VERSION ""

NS_ :

BS_:

BU_: CH DIPF DIPR ETH FC HVI HVS PARTY SDCV VEH VIRT

BO_ 1343 BMS_alertLog: 8 VEH
 SG_ BMS_a025_disSna m25 : 63|1@1+ (1,0) [0|1] ""  gtw
 SG_ BMS_a178_disMia m178 : 63|1@1+ (1,0) [0|1] ""  gtw
 SG_ BMS_a084_vmModuleError m84 : 62|1@1+ (1,0) [0|1] ""  gtw
 SG_ BMS_a025_diSna m25 : 62|1@1+ (1,0) [0|1] ""  gtw
 SG_ BMS_a178_diMia m178 : 62|1@1+ (1,0) [0|1] ""  gtw
 SG_ BMS_a084_udsModuleError m84 : 61|1@1+ (1,0) [0|1] ""  gtw
 SG_ BMS_a084_thermalModuleError m84 : 60|1@1+ (1,0) [0|1] ""  gtw
 SG_ BMS_a084_sleepModuleError m84 : 59|1@1+ (1,0) [0|1] ""  gtw
 SG_ BMS_a084_shuntModuleError m84 : 58|1@1+ (1,0) [0|1] ""  gtw
 SG_ BMS_a084_sensorModuleError m84 : 57|1@1+ (1,0) [0|1] ""  gtw
 SG_ BMS_a082_totalAlertCount m82 : 56|8@1+ (1,0) [0|255] ""  gtw
 SG_ BMS_a084_selfTestModuleError m84 : 56|1@1+ (1,0) [0|1] ""  gtw
 SG_ BMS_a081_totalAlertCount m81 : 56|8@1+ (1,0) [0|255] ""  gtw
 SG_ BMS_a024_packCurrent m24 : 56|8@1- (1,-476) [-1496|544] "A"  gtw
 SG_ BMS_a123_packMinus m123 : 56|8@1- (4,0) [-512|508] "V"  gtw
 SG_ BMS_a039_state m39 : 56|4@1+ (1,0) [0|9] ""  gtw
 SG_ BMS_a084_powerModuleError m84 : 55|1@1+ (1,0) [0|1] ""  gtw
 SG_ BMS_a042_write m42 : 54|1@1+ (1,0) [0|1] ""  gtw
 SG_ BMS_a084_nvramModuleError m84 : 54|1@1+ (1,0) [0|1] ""  gtw
 SG_ BMS_a042_supervisor m42 : 53|1@1+ (1,0) [0|1] ""  gtw
 SG_ BMS_a084_isolationModuleError m84 : 53|1@1+ (1,0) [0|1] ""  gtw
 SG_ BMS_a084_energyModuleError m84 : 52|1@1+ (1,0) [0|1] ""  gtw
 SG_ BMS_a166_dcLinkNegativeV m166 : 52|12@1- (0.25,0) [-512|511.75] "V"  gtw
 SG_ BMS_a165_dcLinkNegativeV m165 : 52|12@1- (0.25,0) [-512|511.75] "V"  gtw
 SG_ BMS_a105_inletTemp m105 : 52|8@1+ (0.5,0) [0|127.5] "C"  gtw
 SG_ BMS_a178_energyError m178 : 51|11@1- (0.1,0) [-102.4|102.3] "kJ"  gtw
 SG_ BMS_a025_energyError m25 : 51|11@1- (0.1,0) [-102.4|102.3] "kJ"  gtw
 SG_ BMS_a168_fcLinkNegativeV m168 : 51|11@1- (0.5,0) [-512|511.5] "V"  gtw
 SG_ BMS_a084_driveLimitsModuleError m84 : 51|1@1+ (1,0) [0|1] ""  gtw
 SG_ BMS_a062_maxBrickVoltage m62 : 51|12@1+ (0.002,0) [0|5] "V"  gtw
 SG_ BMS_a167_fcLinkNegativeV m167 : 51|11@1- (0.5,0) [-512|511.5] "V"  gtw
 SG_ BMS_a084_contactorsModuleError m84 : 50|1@1+ (1,0) [0|1] ""  gtw
 SG_ BMS_a123_state m123 : 50|4@1+ (1,0) [0|9] ""  gtw
 SG_ BMS_a042_master m42 : 49|4@1+ (1,0) [0|15] ""  gtw
 SG_ BMS_a084_chargeStateModuleError m84 : 49|1@1+ (1,0) [0|1] ""  gtw
 SG_ BMS_a084_chargeModuleError m84 : 48|1@1+ (1,0) [0|1] ""  gtw
 SG_ BMS_a138_ovBrickV m138 : 48|16@1+ (7.6293945313e-05,0) [0|4.9999237061] "V"  gtw
 SG_ BMS_a000_alertDataW2 m0 : 48|16@1+ (1,0) [0|65535] ""  X
 SG_ BMS_a130_hviErrorCount m130 : 48|16@1+ (1,0) [0|65535] ""  gtw
 SG_ BMS_a026_deltaPackCurrentPrev m26 : 48|13@1+ (1,0) [0|8191] "A"  gtw
 SG_ BMS_a077_packCurrent m77 : 48|8@1+ (8,-1496) [-1496|540] "A"  gtw
 SG_ BMS_a144_BMS_minor_version m144 : 48|16@1+ (1,0) [0|65535] ""  gtw
 SG_ BMS_a134_maxBrickT m134 : 48|5@1+ (3,-25) [-25|68] "C"  gtw
 SG_ BMS_a137_uvBrickV m137 : 48|16@1+ (7.6293945313e-05,0) [0|4.9999237061] "V"  gtw
 SG_ BMS_a082_fourthAlertId m82 : 48|8@1+ (1,0) [0|180] ""  gtw
 SG_ BMS_a042_data m42 : 48|1@1+ (1,0) [0|1] ""  gtw
 SG_ BMS_a162_socThreshold m162 : 48|16@1+ (1,0) [0|100] "%"  gtw
 SG_ BMS_a034_state m34 : 48|4@1+ (1,0) [0|9] ""  gtw
 SG_ BMS_a146_uvBrickV m146 : 48|16@1+ (7.6293945313e-05,0) [0|4.9999237061] "V"  gtw
 SG_ BMS_a171_stackIndex m171 : 48|8@1+ (1,0) [0|255] ""  gtw
 SG_ BMS_a081_fourthBlockingAlertId m81 : 48|8@1+ (1,0) [0|180] ""  gtw
 SG_ BMS_a039_maxBrickV m39 : 48|8@1+ (0.01,2) [2|4.55] "V"  gtw
 SG_ BMS_a084_brickModuleError m84 : 47|1@1+ (1,0) [0|1] ""  gtw
 SG_ BMS_a084_bmbModuleError m84 : 46|1@1+ (1,0) [0|1] ""  gtw
 SG_ BMS_a084_bsmModuleError m84 : 45|1@1+ (1,0) [0|1] ""  gtw
 SG_ BMS_a105_avgBrickTModule4 m105 : 44|8@1+ (0.5,0) [0|127.5] "C"  gtw
 SG_ BMS_a062_maxBrickVId m62 : 44|7@1+ (1,1) [1|128] ""  gtw
 SG_ BMS_a084_balanceModuleError m84 : 44|1@1+ (1,0) [0|1] ""  gtw
 SG_ BMS_a105_tSenseFailedModule4 m105 : 43|1@1+ (1,0) [0|1] ""  gtw
 SG_ BMS_a084_adcModuleError m84 : 43|1@1+ (1,0) [0|1] ""  gtw
 SG_ BMS_a151_isoNegativeR m151 : 42|10@1+ (10,0) [0|4000] "kOhm"  gtw
 SG_ BMS_a051_bms3V0Ref m51 : 40|12@1+ (0.001,0) [0|4.095] "V"  gtw
 SG_ BMS_a178_batteryPower m178 : 40|11@1- (1,0) [-1024|1023] "kW"  gtw
 SG_ BMS_a019_maxBrickTID m19 : 40|5@1+ (1,0) [0|31] ""  gtw
 SG_ BMS_a166_dcLinkPositiveV m166 : 40|12@1- (0.25,0) [-512|511.75] "V"  gtw
 SG_ BMS_a024_avgDvPrev m24 : 40|16@1- (0.0001,0) [-3.2768|3.2767] "V"  gtw
 SG_ BMS_a165_dcLinkPositiveV m165 : 40|12@1- (0.25,0) [-512|511.75] "V"  gtw
 SG_ BMS_a167_fcLinkPositiveV m167 : 40|11@1- (0.5,0) [-512|511.5] "V"  gtw
 SG_ BMS_a039_packCurrent m39 : 40|8@1+ (8,-1496) [-1496|544] "A"  gtw
 SG_ BMS_a146_uvBrickVID m146 : 40|7@1+ (1,1) [1|128] ""  gtw
 SG_ BMS_a044_assertData m44 : 40|16@1+ (1,0) [0|65535] ""  gtw
 SG_ BMS_a069_minBrickV m69 : 40|8@1+ (0.01,2) [2|4.55] "V"  gtw
 SG_ BMS_a077_packTargetCurrent m77 : 40|8@1+ (8,-1496) [-1496|540] "A"  gtw
 SG_ BMS_a106_inletTemp m106 : 40|8@1+ (0.5,0) [0|127.5] "C"  gtw
 SG_ BMS_a137_uvBrickVID m137 : 40|7@1+ (1,1) [1|128] ""  gtw
 SG_ BMS_a034_packNegativeRatio m34 : 40|8@1+ (0.1,0) [0.1|25.5] "-"  gtw
 SG_ BMS_a134_minBrickV m134 : 40|8@1+ (0.01,2) [2|4.55] "V"  gtw
 SG_ BMS_a145_numBricksChanged m145 : 40|7@1+ (1,0) [0|108] ""  gtw
 SG_ BMS_a084_vcfResource m84 : 40|3@1+ (1,0) [0|5] ""  gtw
 SG_ BMS_a136_maxBrickT m136 : 40|8@1+ (0.4,-20) [-20|82] "C"  gtw
 SG_ BMS_a025_batteryPower m25 : 40|11@1- (1,0) [-1024|1023] "kW"  gtw
 SG_ BMS_a064_maxBrickSOC m64 : 40|8@1+ (0.5,0) [0|100] "PCT"  gtw
 SG_ BMS_a081_thirdBlockingAlertId m81 : 40|8@1+ (1,0) [0|180] ""  gtw
 SG_ BMS_a022_chargeAccumulatorLimit m22 : 40|23@1+ (10,0) [0|83886070] "A^2s"  gtw
 SG_ BMS_a168_fcLinkPositiveV m168 : 40|11@1- (0.5,0) [-512|511.5] "V"  gtw
 SG_ BMS_a123_isoR m123 : 40|10@1+ (10,0) [0|4000] "kOhm"  gtw
 SG_ BMS_a082_thirdAlertId m82 : 40|8@1+ (1,0) [0|180] ""  gtw
 SG_ BMS_a138_ovBrickVID m138 : 40|7@1+ (1,1) [1|128] ""  gtw
 SG_ BMS_a084_pcsResource m84 : 37|3@1+ (1,0) [0|5] ""  gtw
 SG_ BMS_a076_tetheringActive m76 : 37|1@1+ (1,0) [0|1] ""  gtw
 SG_ BMS_a156_VrefStatus m156 : 36|1@1+ (1,0) [0|1] ""  gtw
 SG_ BMS_a039_packContactorState m39 : 36|4@1+ (1,0) [0|9] ""  gtw
 SG_ BMS_a037_floodPort2Voltage m37 : 35|12@1+ (0.001,0) [0|3.3] "V"  gtw
 SG_ BMS_a105_avgBrickTModule3 m105 : 35|8@1+ (0.5,0) [0|127.5] "C"  gtw
 SG_ BMS_a084_cpResource m84 : 34|3@1+ (1,0) [0|5] ""  gtw
 SG_ BMS_a105_tSenseFailedModule3 m105 : 34|1@1+ (1,0) [0|1] ""  gtw
 SG_ BMS_a034_packPositiveRatio m34 : 32|8@1+ (0.1,0) [0.1|25.5] "-"  gtw
 SG_ BMS_a130_hvsErrorCount m130 : 32|16@1+ (1,0) [0|65535] ""  gtw
 SG_ BMS_a081_secondBlockingAlertId m81 : 32|8@1+ (1,0) [0|180] ""  gtw
 SG_ BMS_a077_maxBrickV m77 : 32|8@1+ (0.01,2) [2|4.55] "V"  gtw
 SG_ BMS_a037_floodPort2State m37 : 32|3@1+ (1,0) [0|4] ""  gtw
 SG_ BMS_a136_activeCoolingTarget m136 : 32|8@1+ (0.4,-20) [-20|82] "C"  gtw
 SG_ BMS_a035_mode m35 : 32|3@1+ (1,0) [0|5] ""  gtw
 SG_ BMS_a018_uvBrickV m18 : 32|16@1+ (7.6293945313e-05,0) [0|4.9999237061] "V"  gtw
 SG_ BMS_a064_maxBrickSOCID m64 : 32|7@1+ (1,1) [1|128] "-"  gtw
 SG_ BMS_a000_alertDataW1 m0 : 32|16@1+ (1,0) [0|65535] ""  X
 SG_ BMS_a162_minSoc m162 : 32|16@1+ (1,0) [0|100] "%"  gtw
 SG_ BMS_a017_ovBrickV m17 : 32|16@1+ (7.6293945313e-05,0) [0|4.9999237061] "V"  gtw
 SG_ BMS_a069_minBrickVLimit m69 : 32|8@1+ (0.01,2) [2|4.55] "V"  gtw
 SG_ BMS_a045_exceptionRegisterData m45 : 32|32@1+ (1,0) [0|4294967295] ""  gtw
 SG_ BMS_a144_HVP_minor_version m144 : 32|16@1+ (1,0) [0|65535] ""  gtw
 SG_ BMS_a156_bmbDeviceId m156 : 32|4@1+ (1,0) [0|15] ""  gtw
 SG_ BMS_a138_packCurrent m138 : 32|8@1+ (8,-1496) [-1496|540] "A"  gtw
 SG_ BMS_a145_maxSocChangeBrickID m145 : 32|7@1+ (1,1) [1|108] ""  gtw
 SG_ BMS_a061_ovBrickV m61 : 32|16@1+ (7.6293945313e-05,0) [0|4.9999237061] "V"  gtw
 SG_ BMS_a082_secondAlertId m82 : 32|8@1+ (1,0) [0|180] ""  gtw
 SG_ BMS_a151_isoPositiveR m151 : 32|10@1+ (10,0) [0|4000] "kOhm"  gtw
 SG_ BMS_a046_taskStackWatermark m46 : 32|12@1+ (1,0) [0|4095] ""  gtw
 SG_ BMS_a026_deltaPackCurrent m26 : 32|13@1+ (1,0) [0|8191] "A"  gtw
 SG_ BMS_a123_packPlus m123 : 32|8@1+ (4,0) [0|1020] "V"  gtw
 SG_ BMS_a021_packCurrent m21 : 32|8@1+ (8,-1496) [-1496|540] "A"  gtw
 SG_ BMS_a146_packCurrent m146 : 32|8@1+ (8,-1496) [-1496|540] "A"  gtw
 SG_ BMS_a134_minBrickVLimit m134 : 32|8@1+ (0.01,2) [2|4.55] "V"  gtw
 SG_ BMS_a139_dcLinkVoltage m139 : 32|16@1+ (0.01,0) [0|655.35] "V"  gtw
 SG_ BMS_a141_singleTeslaErrorMask m141 : 32|16@1+ (1,0) [0|65535] ""  gtw
 SG_ BMS_a137_packCurrent m137 : 32|8@1+ (8,-1496) [-1496|540] "A"  gtw
 SG_ BMS_a062_minBrickVoltage m62 : 32|12@1+ (0.002,0) [0|5] "V"  gtw
 SG_ BMS_a053_modelT m53 : 32|8@1+ (0.4,-20) [-20|82] "C"  gtw
 SG_ BMS_a059_packVoltage m59 : 32|16@1+ (0.01,0) [0|655.35] "V"  gtw
 SG_ BMS_a171_sumBrickVoltage m171 : 32|16@1+ (0.01,0) [0|655.35] "V"  gtw
 SG_ BMS_a106_avgBrickT m106 : 32|8@1+ (0.5,0) [0|127.5] "C"  gtw
 SG_ BMS_a132_multiTeslaErrorMask m132 : 32|16@1+ (1,0) [0|65535] ""  gtw
 SG_ BMS_a019_maxBrickT m19 : 32|8@1+ (0.4,-20) [-20|82] "C"  gtw
 SG_ BMS_a084_bmsResource m84 : 31|3@1+ (1,0) [0|5] ""  gtw
 SG_ BMS_a167_dcLinkNegativeV m167 : 29|11@1- (0.5,0) [-512|511.5] "V"  gtw
 SG_ BMS_a168_dcLinkNegativeV m168 : 29|11@1- (0.5,0) [-512|511.5] "V"  gtw
 SG_ BMS_a051_hvp3V0Ref m51 : 28|12@1+ (0.001,0) [0|4.095] "V"  gtw
 SG_ BMS_a166_packNegativeV m166 : 28|12@1- (0.25,0) [-512|511.75] "V"  gtw
 SG_ BMS_a084_hvpResource m84 : 28|3@1+ (1,0) [0|5] ""  gtw
 SG_ BMS_a163_switchStateRequest m163 : 28|3@1+ (1,0) [0|5] ""  gtw
 SG_ BMS_a165_packNegativeV m165 : 28|12@1- (0.25,0) [-512|511.75] "V"  gtw
 SG_ BMS_a025_slavePower m25 : 27|11@1- (1,0) [-1024|1023] "kW"  gtw
 SG_ BMS_a178_slavePower m178 : 27|11@1- (1,0) [-1024|1023] "kW"  gtw
 SG_ BMS_a069_minBrickT m69 : 27|5@1- (3,24) [-25|68] "C"  gtw
 SG_ BMS_a105_avgBrickTModule2 m105 : 26|8@1+ (0.5,0) [0|127.5] "C"  gtw
 SG_ BMS_a035_state m35 : 26|4@1+ (1,0) [0|9] ""  gtw
 SG_ BMS_a039_packVoltage m39 : 26|10@1+ (1,0) [0|1023] "V"  gtw
 SG_ BMS_a084_vehBusResource m84 : 25|3@1+ (1,0) [0|5] ""  gtw
 SG_ BMS_a105_tSenseFailedModule2 m105 : 25|1@1+ (1,0) [0|1] ""  gtw
 SG_ BMS_a050_MIA_numSnaReadings m50 : 24|8@1+ (1,0) [0|255] ""  gtw
 SG_ BMS_a082_firstAlertId m82 : 24|8@1+ (1,0) [0|180] ""  gtw
 SG_ BMS_a064_minBrickSOC m64 : 24|8@1+ (0.5,0) [0|100] "PCT"  gtw
 SG_ BMS_a136_coolantInletT m136 : 24|8@1+ (0.4,-20) [-20|82] "C"  gtw
 SG_ BMS_a122_ThermistorFailCount m122 : 24|5@1+ (1,0) [0|31] ""  gtw
 SG_ BMS_a131_deltaV m131 : 24|16@1+ (0.0001,0) [0|6.5535] "V"  gtw
 SG_ BMS_a055_disUnhealthy m55 : 24|1@1+ (1,0) [0|1] ""  gtw
 SG_ BMS_a023_ovStackV m23 : 24|16@1+ (0.00128,0) [0|83.8848] "V"  gtw
 SG_ BMS_a123_minBrickT m123 : 24|8@1+ (0.4,-20) [-20|82] "C"  gtw
 SG_ BMS_a053_thermistorT m53 : 24|8@1+ (0.4,-20) [-20|82] "C"  gtw
 SG_ BMS_a019_activeCoolingTarget m19 : 24|8@1+ (0.4,-20) [-20|82] "C"  gtw
 SG_ BMS_a071_transitionAlertId m71 : 24|10@1+ (1,0) [0|1023] ""  gtw
 SG_ BMS_a077_maxBrickVTarget m77 : 24|8@1+ (0.01,2) [2|4.55] "V"  gtw
 SG_ BMS_a151_minBrickT m151 : 24|8@1+ (0.4,-20) [-20|82] "C"  gtw
 SG_ BMS_a043_traceDump m43 : 24|32@1+ (1,0) [0|4294967295] ""  gtw
 SG_ BMS_a045_exceptionRegisterIndex m45 : 24|3@1+ (1,0) [0|7] ""  gtw
 SG_ BMS_a044_assertLine m44 : 24|16@1+ (1,0) [0|65535] ""  gtw
 SG_ BMS_a062_minBrickVId m62 : 24|7@1+ (1,1) [1|128] ""  gtw
 SG_ BMS_a061_ovBrickVID m61 : 24|7@1+ (1,1) [1|128] ""  gtw
 SG_ BMS_a129_deltaV m129 : 24|16@1+ (0.0001,0) [0|6.5535] "V"  gtw
 SG_ BMS_a146_state m146 : 24|4@1+ (1,0) [0|9] ""  gtw
 SG_ BMS_a106_maxBrickT m106 : 24|8@1+ (0.5,0) [0|127.5] "C"  gtw
 SG_ BMS_a138_ovMinDeltaBrickV m138 : 24|8@1- (0.02,0.0) [-2.56|2.54] "V"  gtw
 SG_ BMS_a017_ovBrickVID m17 : 24|7@1+ (1,1) [1|128] ""  gtw
 SG_ BMS_a137_maxUvDeltaBrickV m137 : 24|8@1- (0.02,0.0) [-2.56|2.54] "V"  gtw
 SG_ BMS_a069_SOC m69 : 24|3@1+ (2.5,5) [5|20] "PCT"  gtw
 SG_ BMS_a024_deltaV m24 : 24|16@1- (0.0001,0) [-3.2768|3.2767] "V"  gtw
 SG_ BMS_a018_uvBrickVID m18 : 24|7@1+ (1,1) [1|128] ""  gtw
 SG_ BMS_a107_MIA_numSnaReadings m107 : 24|8@1+ (1,0) [0|255] ""  gtw
 SG_ BMS_a021_currentLimit m21 : 24|8@1+ (8,-1496) [-1496|540] "A"  gtw
 SG_ BMS_a134_SOC m134 : 24|8@1+ (1,0) [0|100] "PCT"  gtw
 SG_ BMS_a163_switchState m163 : 24|4@1+ (1,0) [0|9] ""  gtw
 SG_ BMS_a081_firstBlockingAlertId m81 : 24|8@1+ (1,0) [0|180] ""  gtw
 SG_ BMS_a055_diUnhealthy m55 : 23|1@1+ (1,0) [0|1] ""  gtw
 SG_ BMS_a084_hvsBusResource m84 : 22|3@1+ (1,0) [0|5] ""  gtw
 SG_ BMS_a055_invalidPackVoltageData m55 : 22|1@1+ (1,0) [0|1] ""  gtw
 SG_ BMS_a055_invalidModuleThermistor m55 : 21|1@1+ (1,0) [0|1] ""  gtw
 SG_ BMS_a099_bmbChainBreakType m99 : 21|2@1+ (1,0) [0|3] ""  gtw
 SG_ BMS_a163_switchStateRequestPrev m163 : 21|3@1+ (1,0) [0|5] ""  gtw
 SG_ BMS_a158_hvpFaultsMia m158 : 20|1@1+ (1,0) [0|1] ""  gtw
 SG_ BMS_a055_invalidAmbientTemperatu m55 : 20|1@1+ (1,0) [0|1] ""  gtw
 SG_ BMS_a071_state m71 : 20|4@1+ (1,0) [0|9] ""  gtw
 SG_ BMS_a158_contactorStateMia m158 : 19|1@1+ (1,0) [0|1] ""  gtw
 SG_ BMS_a043_traceIndex m43 : 19|4@1+ (1,0) [0|15] ""  gtw
 SG_ BMS_a055_invalidPtInletTemperatu m55 : 19|1@1+ (1,0) [0|1] ""  gtw
 SG_ BMS_a084_hviBusResource m84 : 19|3@1+ (1,0) [0|5] ""  gtw
 SG_ BMS_a046_taskStackAllocated m46 : 19|12@1+ (1,0) [0|4095] ""  gtw
 SG_ BMS_a037_floodPort1Voltage m37 : 19|12@1+ (0.001,0) [0|3.3] "V"  gtw
 SG_ BMS_a045_exceptionRegisterType m45 : 19|3@1+ (1,0) [0|6] ""  gtw
 SG_ BMS_a001_bmsPackType m1 : 18|4@1+ (1,0) [0|8] ""  gtw
 SG_ BMS_a055_invalidBmbVoltageData m55 : 18|1@1+ (1,0) [0|1] ""  gtw
 SG_ BMS_a168_dcLinkPositiveV m168 : 18|11@1- (0.5,0) [-512|511.5] "V"  gtw
 SG_ BMS_a158_brickMeasurementMia m158 : 18|1@1+ (1,0) [0|1] ""  gtw
 SG_ BMS_a167_dcLinkPositiveV m167 : 18|11@1- (0.5,0) [-512|511.5] "V"  gtw
 SG_ BMS_a158_packTempMeasurementMia m158 : 17|1@1+ (1,0) [0|1] ""  gtw
 SG_ BMS_a055_invalidShuntData m55 : 17|1@1+ (1,0) [0|1] ""  gtw
 SG_ BMS_a167_fcContNegativeAuxOpen m167 : 17|1@1+ (1,0) [0|1] ""  gtw
 SG_ BMS_a163_switchStatePrev m163 : 17|4@1+ (1,0) [0|9] ""  gtw
 SG_ BMS_a022_chargeAccumulatorValue m22 : 17|23@1+ (10,0) [0|83886070] "A^2s"  gtw
 SG_ BMS_a157_HVP_contactorStateMia m157 : 17|1@1+ (1,0) [0|1] ""  gtw
 SG_ BMS_a168_fcContNegativeAuxOpen m168 : 17|1@1+ (1,0) [0|1] ""  gtw
 SG_ BMS_a105_avgBrickTModule1 m105 : 17|8@1+ (0.5,0) [0|127.5] "C"  gtw
 SG_ BMS_a026_packCurrent m26 : 16|13@1+ (1,0) [0|8191] "A"  gtw
 SG_ BMS_a084_sleepState m84 : 16|3@1+ (1,0) [0|6] ""  gtw
 SG_ BMS_a060_fcLinkDecayTime m60 : 16|10@1+ (2,0) [0|2046] "mS"  gtw
 SG_ BMS_a121_nvramErrorType m121 : 16|2@1+ (1,0) [0|2] ""  gtw
 SG_ BMS_a107_MIA_numBadReadings m107 : 16|8@1+ (1,0) [0|255] ""  gtw
 SG_ BMS_a025_masterPower m25 : 16|11@1- (1,0) [-1024|1023] "kW"  gtw
 SG_ BMS_a062_state m62 : 16|4@1+ (1,0) [0|9] ""  gtw
 SG_ BMS_a064_minBrickSOCID m64 : 16|7@1+ (1,1) [1|128] "-"  gtw
 SG_ BMS_a047_taskID m47 : 16|3@1+ (1,0) [0|6] ""  gtw
 SG_ BMS_a134_packCurrent m134 : 16|8@1- (1,0) [-128|127] "A"  gtw
 SG_ BMS_a144_HVP_major_version m144 : 16|16@1+ (1,0) [0|65535] ""  gtw
 SG_ BMS_a105_tSenseFailedModule1 m105 : 16|1@1+ (1,0) [0|1] ""  gtw
 SG_ BMS_a165_packPositiveV m165 : 16|12@1- (0.25,0) [-512|511.75] "V"  gtw
 SG_ BMS_a129_brickID m129 : 16|8@1+ (1,1) [1|256] "-"  gtw
 SG_ BMS_a017_packCurrent m17 : 16|8@1+ (8,-1500) [-1500|540] "A"  gtw
 SG_ BMS_a063_cpFaultInV m63 : 16|12@1+ (0.001,0) [0|4.095] "V"  gtw
 SG_ BMS_a037_floodPort1State m37 : 16|3@1+ (1,0) [0|4] ""  gtw
 SG_ BMS_a054_verSupplyV m54 : 16|16@1+ (0.001,0) [0|65.535] "V"  gtw
 SG_ BMS_a145_maxSocChange m145 : 16|11@1- (0.1,0.0) [-100|100] "%"  gtw
 SG_ BMS_a178_masterPower m178 : 16|11@1- (1,0) [-1024|1023] "kW"  gtw
 SG_ BMS_a053_thmMdlModuleID m53 : 16|5@1+ (1,0) [0|31] ""  gtw
 SG_ BMS_a071_stateRequest m71 : 16|4@1+ (1,0) [0|9] ""  gtw
 SG_ BMS_a136_maxBrickTID m136 : 16|5@1+ (1,0) [0|31] ""  gtw
 SG_ BMS_a045_ivorNumber m45 : 16|3@1+ (1,0) [0|7] ""  gtw
 SG_ BMS_a087_blockingAlert m87 : 16|8@1+ (1,0) [0|255] ""  gtw
 SG_ BMS_a106_minBrickT m106 : 16|8@1+ (0.5,0) [0|127.5] "C"  gtw
 SG_ BMS_a021_chargeViolation m21 : 16|1@1+ (1,0) [0|1] ""  gtw
 SG_ BMS_a043_taskID m43 : 16|3@1+ (1,0) [0|6] ""  gtw
 SG_ BMS_a069_packCurrent m69 : 16|8@1- (1,0) [-128|127] "A"  gtw
 SG_ BMS_a131_brickID m131 : 16|8@1+ (1,1) [1|256] "-"  gtw
 SG_ BMS_a168_fcContPositiveAuxOpen m168 : 16|1@1+ (1,0) [0|1] ""  gtw
 SG_ BMS_a077_chargeErrType m77 : 16|1@1+ (1,0) [0|1] ""  gtw
 SG_ BMS_a019_coolantInletT m19 : 16|8@1+ (0.4,-20) [-20|82] "C"  gtw
 SG_ BMS_a046_taskID m46 : 16|3@1+ (1,0) [0|6] ""  gtw
 SG_ BMS_a024_brickID m24 : 16|8@1+ (1,1) [1|256] "-"  gtw
 SG_ BMS_a137_SOC m137 : 16|8@1+ (1,0) [0|100] "PCT"  gtw
 SG_ BMS_a169_DCAndFCContactorsWelded m169 : 16|1@1+ (1,0) [0|1] ""  gtw
 SG_ BMS_a000_alertDataW0 m0 : 16|16@1+ (1,0) [0|65535] ""  X
 SG_ BMS_a132_multiVendorErrorMask m132 : 16|16@1+ (1,0) [0|65535] ""  gtw
 SG_ BMS_a035_isoR m35 : 16|10@1+ (10,0) [0|4000] "kOhm"  gtw
 SG_ BMS_a055_vcfrontMia m55 : 16|1@1+ (1,0) [0|1] ""  gtw
 SG_ BMS_a122_ThermistorId m122 : 16|5@1+ (1,0) [0|31] ""  gtw
 SG_ BMS_a034_packVoltage m34 : 16|10@1+ (1,0) [0|1023] "V"  gtw
 SG_ BMS_a082_stateRequest m82 : 16|4@1+ (1,0) [0|9] ""  gtw
 SG_ BMS_a042_accessAddress m42 : 16|32@1+ (1,0) [0|4294967295] ""  gtw
 SG_ BMS_a090_GTWmessageTout m90 : 16|4@1+ (1,0) [0|8] ""  gtw
 SG_ BMS_a151_maxBrickT m151 : 16|8@1+ (0.4,-20) [-20|82] "C"  gtw
 SG_ BMS_a158_shuntCurrentMia m158 : 16|1@1+ (1,0) [0|1] ""  gtw
 SG_ BMS_a023_ovStackDeviceID m23 : 16|5@1+ (1,1) [1|32] "-"  gtw
 SG_ BMS_a156_VrefSample m156 : 16|16@1+ (0.0001,0) [0|10] "V"  gtw
 SG_ BMS_a171_stackVoltage m171 : 16|16@1- (0.00128,0) [-41.94304|41.94176] "V"  gtw
 SG_ BMS_a022_chargeAccumulatorViolat m22 : 16|1@1+ (1,0) [0|1] ""  gtw
 SG_ BMS_a083_packContactorRequest m83 : 16|3@1+ (1,0) [0|5] ""  gtw
 SG_ BMS_a162_dischargePower_W m162 : 16|16@1- (1,0) [-30000|30000] "W"  gtw
 SG_ BMS_a141_singleVendorErrorMask m141 : 16|16@1+ (1,0) [0|65535] ""  gtw
 SG_ BMS_a048_logId m48 : 16|4@1+ (1,0) [0|15] ""  gtw
 SG_ BMS_a166_packPositiveV m166 : 16|12@1- (0.25,0) [-512|511.75] "V"  gtw
 SG_ BMS_a157_HVP_bmsChargeRegulation m157 : 16|1@1+ (1,0) [0|1] ""  gtw
 SG_ BMS_a138_SOC m138 : 16|8@1+ (1,0) [0|100] "PCT"  gtw
 SG_ BMS_a139_packVoltage m139 : 16|16@1- (0.01,0) [-327.68|327.67] "V"  gtw
 SG_ BMS_a075_chargeType m75 : 16|1@1+ (1,0) [0|1] ""  gtw
 SG_ BMS_a167_fcContPositiveAuxOpen m167 : 16|1@1+ (1,0) [0|1] ""  gtw
 SG_ BMS_a099_bmbID m99 : 16|5@1+ (1,0) [0|31] ""  gtw
 SG_ BMS_a146_maxBrickV m146 : 16|8@1+ (0.01,2) [2|4.55] "V"  gtw
 SG_ BMS_a001_gatewayPackType m1 : 16|2@1+ (1,0) [0|2] ""  gtw
 SG_ BMS_a081_stateRequest m81 : 16|4@1+ (1,0) [0|9] ""  gtw
 SG_ BMS_a059_sumBrickVoltages m59 : 16|16@1+ (0.01,0) [0|655.35] "V"  gtw
 SG_ BMS_a044_assertId m44 : 16|4@1+ (1,0) [0|10] ""  gtw
 SG_ BMS_a164_regenPower m164 : 16|32@1+ (1,0) [0|4294967295] "W"  gtw
 SG_ BMS_a050_MIA_numBadReadings m50 : 16|8@1+ (1,0) [0|255] ""  gtw
 SG_ BMS_a039_dcLinkVoltage m39 : 16|10@1+ (1,0) [0|1023] "V"  gtw
 SG_ BMS_a061_packCurrent m61 : 16|8@1+ (8,-1500) [-1500|540] "A"  gtw
 SG_ BMS_a076_netAh m76 : 16|21@1- (0.01,0) [-10485.76|10485.75] "Ah"  gtw
 SG_ BMS_a130_vehErrorCount m130 : 16|16@1+ (1,0) [0|65535] ""  gtw
 SG_ BMS_a170_limpModeActive m170 : 16|1@1+ (1,0) [0|1] ""  gtw
 SG_ BMS_a163_contactorType m163 : 16|1@1+ (1,0) [0|1] ""  gtw
 SG_ BMS_a123_maxBrickT m123 : 16|8@1+ (0.4,-20) [-20|82] "C"  gtw
 SG_ BMS_a051_hvp1V5Ref m51 : 16|12@1+ (0.001,0) [0|4.095] "V"  gtw
 SG_ BMS_a018_packCurrent m18 : 16|8@1+ (8,-1496) [-1496|540] "A"  gtw
 SG_ BMS_alertSet : 15|1@1+ (1,0) [0|1] ""  gtw
 SG_ BMS_alertID M : 0|8@1+ (1,0) [0|180] ""  gtw

BO_ 1574 UDS_epbrRequest: 8 VEH
 SG_ UDS_epbrRequestData_L : 39|32@0+ (1,0) [0|4294967295] ""  epbr
 SG_ UDS_epbrRequestData_H : 7|32@0+ (1,0) [0|4294967295] ""  epbr

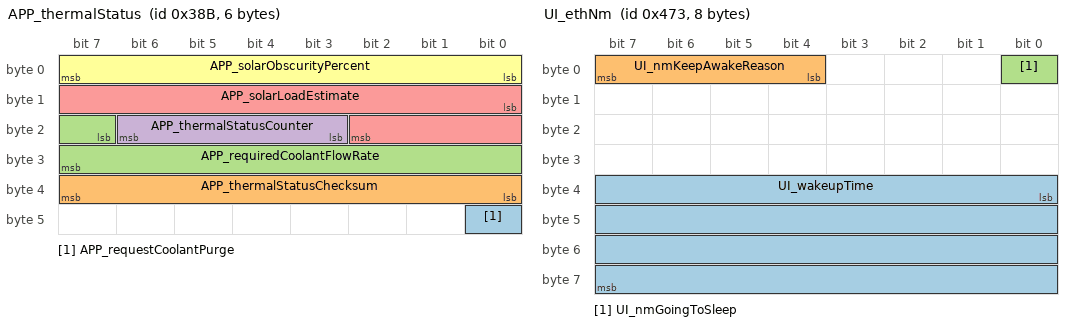
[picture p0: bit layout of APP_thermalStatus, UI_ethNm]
BO_ 907 APP_thermalStatus: 6 VEH
 SG_ APP_requestCoolantPurge : 40|1@1+ (1,0) [0|1] ""  gtw
 SG_ APP_thermalStatusChecksum : 32|8@1+ (1,0) [0|255] ""  X
 SG_ APP_requiredCoolantFlowRate : 23|9@1+ (0.1,0) [0|40] "LPM"  gtw
 SG_ APP_thermalStatusCounter : 19|4@1+ (1,0) [0|15] ""  X
 SG_ APP_solarLoadEstimate : 8|11@1+ (1,0) [0|1500] "W/m2"  X
 SG_ APP_solarObscurityPercent : 0|8@1+ (0.5,-25) [-25|100] "percent"  X

BO_ 1544 UDS_vcrightRequest: 8 VEH
 SG_ UDS_vcrightRequestData_L : 39|32@0+ (1,0) [0|4294967295] ""  vcright
 SG_ UDS_vcrightRequestData_H : 7|32@0+ (1,0) [0|4294967295] ""  vcright

BO_ 1329 VCSEC_alertCleared: 1 VEH
 SG_ VCSEC_alertClearedID : 0|8@1+ (1,0) [0|210] ""  X

BO_ 1139 UI_ethNm: 8 VEH
 SG_ UI_wakeupTime : 32|32@1+ (1,0) [0|4294967295] ""  X
 SG_ UI_nmKeepAwakeReason : 4|4@1+ (1,0) [0|15] ""  vcfront
 SG_ UI_nmGoingToSleep : 0|1@1+ (1,0) [0|1] ""  X

BO_ 1280 UI_debugECU: 2 VEH
 SG_ UI_PM_debugAt100Hz m3 : 9|1@1+ (1,0) [0|1] ""  pm
 SG_ UI_PMS_debugAt100Hz m4 : 9|1@1+ (1,0) [0|1] ""  pms
 SG_ UI_BMS_debugDisable m5 : 9|1@1+ (1,0) [0|1] ""  bms
 SG_ UI_BMS_debugAllEnable m5 : 8|1@1+ (1,0) [0|1] ""  bms
 SG_ UI_DIS_debugEnable m2 : 8|1@1+ (1,0) [0|1] ""  dis
 SG_ UI_PMS_debugEnable m4 : 8|1@1+ (1,0) [0|1] ""  pms
 SG_ UI_DI_debugEnable m1 : 8|1@1+ (1,0) [0|1] ""  di
 SG_ UI_PM_debugEnable m3 : 8|1@1+ (1,0) [0|1] ""  pm
 SG_ UI_VCRIGHT_debugEnable m6 : 8|1@1+ (1,0) [0|1] ""  vcright
 SG_ UI_VCFRONT_debugEnable m7 : 3|1@1+ (1,0) [0|1] ""  vcfront
 SG_ UI_debugEcuTarget M : 0|3@1+ (1,0) [1|7] ""  bms

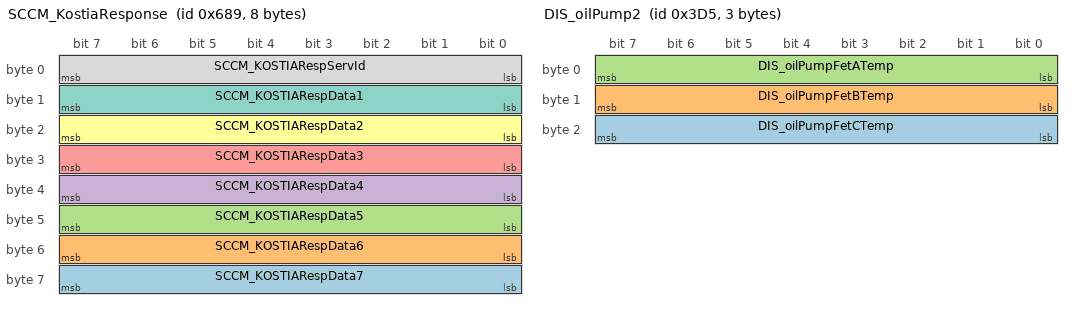
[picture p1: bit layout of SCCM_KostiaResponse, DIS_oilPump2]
BO_ 1673 SCCM_KostiaResponse: 8 VEH
 SG_ SCCM_KOSTIARespData7 : 56|8@1+ (1,0) [0|255] ""  X
 SG_ SCCM_KOSTIARespData6 : 48|8@1+ (1,0) [0|255] ""  X
 SG_ SCCM_KOSTIARespData5 : 40|8@1+ (1,0) [0|255] ""  X
 SG_ SCCM_KOSTIARespData4 : 32|8@1+ (1,0) [0|255] ""  X
 SG_ SCCM_KOSTIARespData3 : 24|8@1+ (1,0) [0|255] ""  X
 SG_ SCCM_KOSTIARespData2 : 16|8@1+ (1,0) [0|255] ""  X
 SG_ SCCM_KOSTIARespData1 : 8|8@1+ (1,0) [0|255] ""  X
 SG_ SCCM_KOSTIARespServId : 0|8@1+ (1,0) [0|255] ""  X

BO_ 1542 UDS_diRequest: 8 VEH
 SG_ UDS_diRequestData : 7|64@0+ (1,0) [0|18446744073709551615] ""  di

BO_ 1750 PTC_udsResponse: 8 VEH
 SG_ PTC_udsResponseData : 7|64@0+ (1,0) [0|18446744073709551615] ""  gtw

BO_ 1303 FC_identifier: 8 VEH
 SG_ FC_sessionId : 32|32@1+ (1,0) [0|4294967295] ""  dbg
 SG_ FC_id : 0|32@1+ (1,0) [0|4294967295] ""  dbg

BO_ 1940 PMS_xcpResponse: 8 VEH
 SG_ PMS_xcpResponse : 0|64@1+ (1,0) [0|18446744073709551615] ""  dbg

BO_ 969 VCSEC_BLEEndpointInfo: 8 VEH
 SG_ VCSEC_BLEREARPcbaID m2 : 56|8@1+ (1,0) [0|255] ""  gtw
 SG_ VCSEC_BLELEFTPcbaID m0 : 56|8@1+ (1,0) [0|255] ""  gtw
 SG_ VCSEC_BLECENTERPcbaID m3 : 56|8@1+ (1,0) [0|255] ""  gtw
 SG_ VCSEC_BLERIGHTPcbaID m1 : 56|8@1+ (1,0) [0|255] ""  gtw
 SG_ VCSEC_BLERIGHTComponentID m1 : 40|16@1+ (1,0) [0|65535] ""  gtw
 SG_ VCSEC_BLEREARComponentID m2 : 40|16@1+ (1,0) [0|65535] ""  gtw
 SG_ VCSEC_BLECENTERComponentID m3 : 40|16@1+ (1,0) [0|65535] ""  X
 SG_ VCSEC_BLELEFTComponentID m0 : 40|16@1+ (1,0) [0|65535] ""  gtw
 SG_ VCSEC_BLERIGHTCrc m1 : 8|32@1+ (1,0) [0|4294967295] ""  gtw
 SG_ VCSEC_BLEREARCrc m2 : 8|32@1+ (1,0) [0|4294967295] ""  gtw
 SG_ VCSEC_BLERIGHTAppGitHashByte m5 : 8|56@1+ (1,0) [0|72057594037927935] ""  gtw
 SG_ VCSEC_BLEREARAppGitHashByte m6 : 8|56@1+ (1,0) [0|72057594037927935] ""  gtw
 SG_ VCSEC_BLELEFTCrc m0 : 8|32@1+ (1,0) [0|4294967295] ""  gtw
 SG_ VCSEC_BLECENTERCrc m3 : 8|32@1+ (1,0) [0|4294967295] ""  gtw
 SG_ VCSEC_BLELEFTAppGitHashByte m4 : 8|56@1+ (1,0) [0|72057594037927935] ""  gtw
 SG_ VCSEC_BLECENTERAppGitHashByte m7 : 8|56@1+ (1,0) [0|72057594037927935] ""  X
 SG_ VCSEC_BLEEndpointInfoIndex M : 0|3@1+ (1,0) [0|7] ""  gtw

BO_ 545 VCFRONT_LVPowerState: 8 VEH
 SG_ VCFRONT_LVPowerStateChecksum : 56|8@1+ (1,0) [0|255] ""  gtw
 SG_ VCFRONT_LVPowerStateCounter : 52|4@1+ (1,0) [0|15] ""  gtw
 SG_ VCFRONT_uiAudioLVState m0 : 50|2@1+ (1,0) [0|3] ""  X
 SG_ VCFRONT_uiHiCurrentLVState m0 : 48|2@1+ (1,0) [0|3] ""  gtw
 SG_ VCFRONT_vcrightHiCurrentLVState m0 : 46|2@1+ (1,0) [0|3] ""  epbl
 SG_ VCFRONT_vcleftHiCurrentLVState m0 : 44|2@1+ (1,0) [0|3] ""  epbl
 SG_ VCFRONT_ocsLVRequest m0 : 42|2@1+ (1,0) [0|3] ""  vcright
 SG_ VCFRONT_oilPumpRearLVRequest m0 : 40|2@1+ (1,0) [0|3] ""  vcright
 SG_ VCFRONT_oilPumpFrontLVState m0 : 38|2@1+ (1,0) [0|3] ""  X
 SG_ VCFRONT_disLVState m0 : 36|2@1+ (1,0) [0|3] ""  dis
 SG_ VCFRONT_diLVRequest m0 : 34|2@1+ (1,0) [0|3] ""  di
 SG_ VCFRONT_das2HighCurrentLVState m0 : 32|2@1+ (1,0) [0|3] ""  das
 SG_ VCFRONT_das1HighCurrentLVState m0 : 30|2@1+ (1,0) [0|3] ""  das
 SG_ VCFRONT_amplifierLVRequest m0 : 28|2@1+ (1,0) [0|3] ""  vcright
 SG_ VCFRONT_tunerLVRequest m0 : 26|2@1+ (1,0) [0|3] ""  vcright
 SG_ VCFRONT_iBoosterLVState m0 : 24|2@1+ (1,0) [0|3] ""  gtw
 SG_ VCFRONT_rcmLVRequest m0 : 22|2@1+ (1,0) [0|3] ""  epbl
 SG_ VCFRONT_tpmsLVRequest m0 : 20|2@1+ (1,0) [0|3] ""  gtw
 SG_ VCFRONT_sccmLVRequest m0 : 18|2@1+ (1,0) [0|3] ""  epbl
 SG_ VCFRONT_pcsLVState m1 : 16|2@1+ (1,0) [0|3] ""  bms
 SG_ VCFRONT_ptcLVRequest m0 : 16|2@1+ (1,0) [0|3] ""  gtw
 SG_ VCFRONT_hvacCompLVState m0 : 14|2@1+ (1,0) [0|3] ""  X
 SG_ VCFRONT_tasLVState m1 : 14|2@1+ (1,0) [0|3] ""  X
 SG_ VCFRONT_hvcLVRequest m1 : 12|2@1+ (1,0) [0|3] ""  gtw
 SG_ VCFRONT_radcLVState m0 : 12|2@1+ (1,0) [0|3] ""  gtw
 SG_ VCFRONT_epasLVState m1 : 10|2@1+ (1,0) [0|3] ""  gtw
 SG_ VCFRONT_espLVState m0 : 10|2@1+ (1,0) [0|3] ""  epbl
 SG_ VCFRONT_parkLVState m0 : 8|2@1+ (1,0) [0|3] ""  epbl
 SG_ VCFRONT_cpLVRequest m1 : 8|2@1+ (1,0) [0|3] ""  epbl
 SG_ VCFRONT_vehiclePowerState : 5|2@1+ (1,0) [0|3] ""  bms
 SG_ VCFRONT_LVPowerStateIndex M : 0|5@1+ (1,0) [0|1] ""  gtw

BO_ 1641 UDS_KOSTIAsccmRequest: 8 VEH
 SG_ UDS_KOSTIAsccmRequestData : 7|64@0+ (1,0) [0|18446744073709551615] ""  sccm

BO_ 981 DIS_oilPump2: 3 VEH
 SG_ DIS_oilPumpFetCTemp : 16|8@1+ (1,-40) [-40|214] "DegC"  gtw
 SG_ DIS_oilPumpFetBTemp : 8|8@1+ (1,-40) [-40|214] "DegC"  gtw
 SG_ DIS_oilPumpFetATemp : 0|8@1+ (1,-40) [-40|214] "DegC"  gtw

BO_ 798 CP_alertMatrix: 8 VEH
 SG_ CP_a060_lostCommsPCS m0 : 63|1@1+ (1,0) [0|1] ""  gtw
 SG_ CP_a059_swcanError m0 : 62|1@1+ (1,0) [0|1] ""  gtw
 SG_ CP_a058_acChargingBlocked m0 : 61|1@1+ (1,0) [0|1] ""  gtw
 SG_ CP_a057_evseFaulted m0 : 60|1@1+ (1,0) [0|1] ""  gtw
 SG_ CP_a056_proxDisconnected m0 : 59|1@1+ (1,0) [0|1] ""  gtw
 SG_ CP_a055_chargeStoppedNoPilot m0 : 58|1@1+ (1,0) [0|1] ""  gtw
 SG_ CP_a054_cableNotSecured m0 : 57|1@1+ (1,0) [0|1] ""  gtw
 SG_ CP_a053_proxLatchedNoPilot m0 : 56|1@1+ (1,0) [0|1] ""  gtw
 SG_ CP_a052_evseNotSupported m0 : 55|1@1+ (1,0) [0|1] ""  gtw
 SG_ CP_a051_doorInductiveSensorMIA m0 : 54|1@1+ (1,0) [0|1] ""  gtw
 SG_ CP_a050_latchNotConnected m0 : 53|1@1+ (1,0) [0|1] ""  gtw
 SG_ CP_a049_multipleCablesDetected m0 : 52|1@1+ (1,0) [0|1] ""  gtw
 SG_ CP_a048_lostCommsUI m0 : 51|1@1+ (1,0) [0|1] ""  gtw
 SG_ CP_a047_lostCommsVCFRONT m0 : 50|1@1+ (1,0) [0|1] ""  gtw
 SG_ CP_a046_lostCommsEVSE m0 : 49|1@1+ (1,0) [0|1] ""  gtw
 SG_ CP_a045_lostCommsVCSEC m0 : 48|1@1+ (1,0) [0|1] ""  gtw
 SG_ CP_a044_lostCommsHVP m0 : 47|1@1+ (1,0) [0|1] ""  gtw
 SG_ CP_a043_doorPotIrrational m0 : 46|1@1+ (1,0) [0|1] ""  gtw
 SG_ CP_a042_doorAssemblyBroken m0 : 45|1@1+ (1,0) [0|1] ""  gtw
 SG_ CP_a041_doorSensorUnplugged m0 : 44|1@1+ (1,0) [0|1] ""  gtw
 SG_ CP_a040_doNotUse m0 : 43|1@1+ (1,0) [0|1] ""  gtw
 SG_ CP_a039_latchMovement_2 m0 : 42|1@1+ (1,0) [0|1] ""  gtw
 SG_ CP_a038_latchNotBlocking m0 : 41|1@1+ (1,0) [0|1] ""  gtw
 SG_ CP_a037_latchNotEngaged m0 : 40|1@1+ (1,0) [0|1] ""  gtw
 SG_ CP_a036_latchNotDisengaged m0 : 39|1@1+ (1,0) [0|1] ""  gtw
 SG_ CP_a035_latchMovement_1 m0 : 38|1@1+ (1,0) [0|1] ""  gtw
 SG_ CP_a034_calibrationIncomplete m0 : 37|1@1+ (1,0) [0|1] ""  gtw
 SG_ CP_a033_spiOpen m0 : 36|1@1+ (1,0) [0|1] ""  gtw
 SG_ CP_a032_doorOpenExpectedClosed m0 : 35|1@1+ (1,0) [0|1] ""  gtw
 SG_ CP_a031_doorClosedCommandedOpen m0 : 34|1@1+ (1,0) [0|1] ""  gtw
 SG_ CP_a030_busOff m0 : 33|1@1+ (1,0) [0|1] ""  gtw
 SG_ CP_a029_doorClosedProxPilot m0 : 32|1@1+ (1,0) [0|1] ""  gtw
 SG_ CP_a028_insertEnableMismatch m0 : 31|1@1+ (1,0) [0|1] ""  gtw
 SG_ CP_a027_doorSensorOutOfSpec m0 : 30|1@1+ (1,0) [0|1] ""  gtw
 SG_ CP_a026_networkManagement m0 : 29|1@1+ (1,0) [0|1] ""  gtw
 SG_ CP_a025_ledsOC m0 : 28|1@1+ (1,0) [0|1] ""  gtw
 SG_ CP_a024_ledsUC m0 : 27|1@1+ (1,0) [0|1] ""  gtw
 SG_ CP_a023_gbdcSessionFailed m0 : 26|1@1+ (1,0) [0|1] ""  gtw
 SG_ CP_a022_zeroVuv m0 : 25|1@1+ (1,0) [0|1] ""  gtw
 SG_ CP_a021_zeroVov m0 : 24|1@1+ (1,0) [0|1] ""  gtw
 SG_ CP_a020_threeVuv m0 : 23|1@1+ (1,0) [0|1] ""  gtw
 SG_ CP_a019_threeVov m0 : 22|1@1+ (1,0) [0|1] ""  gtw
 SG_ CP_a018_fiveVuv m0 : 21|1@1+ (1,0) [0|1] ""  gtw
 SG_ CP_a017_fiveVov m0 : 20|1@1+ (1,0) [0|1] ""  gtw
 SG_ CP_a016_apsVuv m0 : 19|1@1+ (1,0) [0|1] ""  gtw
 SG_ CP_a015_apsVov m0 : 18|1@1+ (1,0) [0|1] ""  gtw
 SG_ CP_a014_lostCommsCHG m0 : 17|1@1+ (1,0) [0|1] ""  gtw
 SG_ CP_a256_unused m1 : 17|1@1+ (1,0) [0|1] ""  gtw
 SG_ CP_a073_cableNotSecuredCold m1 : 16|1@1+ (1,0) [0|1] ""  gtw
 SG_ CP_a013_lostCommsGTW m0 : 16|1@1+ (1,0) [0|1] ""  gtw
 SG_ CP_a072_latchNotDisengagedCold m1 : 15|1@1+ (1,0) [0|1] ""  gtw
 SG_ CP_a012_ledDriver m0 : 15|1@1+ (1,0) [0|1] ""  gtw
 SG_ CP_a071_LDC1612errorWatchdog m1 : 14|1@1+ (1,0) [0|1] ""  gtw
 SG_ CP_a011_eeprom m0 : 14|1@1+ (1,0) [0|1] ""  gtw
 SG_ CP_a070_doorInductiveSensorReset m1 : 13|1@1+ (1,0) [0|1] ""  gtw
 SG_ CP_a010_pilotRationality m0 : 13|1@1+ (1,0) [0|1] ""  gtw
 SG_ CP_a069_doorInductiveSensorError m1 : 12|1@1+ (1,0) [0|1] ""  gtw
 SG_ CP_a009_coverOpen m0 : 12|1@1+ (1,0) [0|1] ""  gtw
 SG_ CP_a008_memoryError m0 : 11|1@1+ (1,0) [0|1] ""  gtw
 SG_ CP_a068_doorSensorMismatch m1 : 11|1@1+ (1,0) [0|1] ""  gtw
 SG_ CP_a007_watchdog m0 : 10|1@1+ (1,0) [0|1] ""  gtw
 SG_ CP_a067_gbdcConnFault m1 : 10|1@1+ (1,0) [0|1] ""  gtw
 SG_ CP_a066_proxLatchedIdlePilot m1 : 9|1@1+ (1,0) [0|1] ""  gtw
 SG_ CP_a006_lostCommsBMS m0 : 9|1@1+ (1,0) [0|1] ""  gtw
 SG_ CP_a005_gbdcLiveDisconnect m0 : 8|1@1+ (1,0) [0|1] ""  gtw
 SG_ CP_a065_selfTestFailed m1 : 8|1@1+ (1,0) [0|1] ""  gtw
 SG_ CP_a004_proximityRationality m0 : 7|1@1+ (1,0) [0|1] ""  gtw
 SG_ CP_a064_superchargingBlocked m1 : 7|1@1+ (1,0) [0|1] ""  gtw
 SG_ CP_a003_canError m0 : 6|1@1+ (1,0) [0|1] ""  gtw
 SG_ CP_a063_scUpdateInProgress m1 : 6|1@1+ (1,0) [0|1] ""  gtw
 SG_ CP_a002_canTx m0 : 5|1@1+ (1,0) [0|1] ""  gtw
 SG_ CP_a062_scOutOfService m1 : 5|1@1+ (1,0) [0|1] ""  gtw
 SG_ CP_a001_canRx m0 : 4|1@1+ (1,0) [0|1] ""  gtw
 SG_ CP_a061_uhfReceiverMIA m1 : 4|1@1+ (1,0) [0|1] ""  gtw
 SG_ CP_matrixIndex M : 0|4@1+ (1,0) [0|15] ""  gtw

BO_ 793 VCSEC_info: 8 VEH
 SG_ VCSEC_infoComponentId m10 : 48|16@1+ (1,0) [0|65535] ""  gtw
 SG_ VCSEC_infoSubUsageId m11 : 48|16@1+ (1,0) [0|65535] ""  gtw
 SG_ VCSEC_infoSubcomponent4 m31 : 32|32@1+ (1,0) [0|4294967295] ""  gtw
 SG_ VCSEC_infoSubcomponent1 m16 : 32|32@1+ (1,0) [0|4294967295] ""  gtw
 SG_ VCSEC_infoAppCrc m13 : 32|32@1+ (1,0) [0|4294967295] ""  gtw
 SG_ VCSEC_infoSubcomponent3 m24 : 32|32@1+ (1,0) [0|4294967295] ""  gtw
 SG_ VCSEC_infoUsageId m11 : 32|16@1+ (1,0) [0|65535] ""  gtw
 SG_ VCSEC_infoSubcomponent2 m23 : 32|32@1+ (1,0) [0|4294967295] ""  gtw
 SG_ VCSEC_infoHardwareId m10 : 32|16@1+ (1,0) [0|65535] ""  gtw
 SG_ VCSEC_infoBootCrc m20 : 24|32@1+ (1,0) [0|4294967295] ""  gtw
 SG_ VCSEC_infoBuildConfigId m10 : 16|16@1+ (1,0) [0|65535] ""  gtw
 SG_ VCSEC_infoAssemblyId m11 : 16|8@1+ (1,0) [0|255] ""  gtw
 SG_ VCSEC_infoBootUdsProtoVersion m20 : 8|16@1+ (1,0) [0|65535] ""  gtw
 SG_ VCSEC_infoPlatformType m19 : 8|8@1+ (1,0) [0|255] ""  gtw
 SG_ VCSEC_infoAppGitHash m17 : 8|56@1+ (1,0) [0|72057594037927935] ""  gtw
 SG_ VCSEC_infoBuildType m10 : 8|3@1+ (1,0) [0|4] ""  gtw
 SG_ VCSEC_infoBootGitHash m18 : 8|56@1+ (1,0) [0|72057594037927935] ""  gtw
 SG_ VCSEC_infoPcbaId m11 : 8|8@1+ (1,0) [0|255] ""  gtw
 SG_ VCSEC_infoIndex M : 0|8@1+ (1,0) [0|255] ""  gtw

BO_ 950 DI_odometerStatus: 4 VEH
 SG_ DI_odometer : 0|32@1+ (0.001,0) [0|4294967.294] "km"  gtw

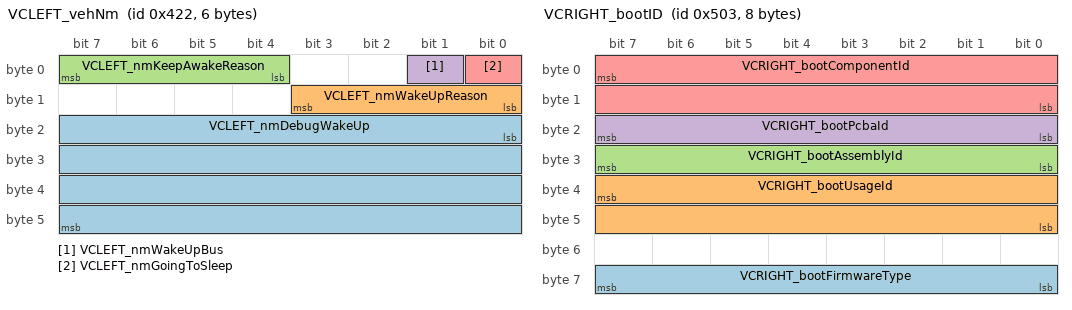
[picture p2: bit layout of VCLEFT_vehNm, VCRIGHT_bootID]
BO_ 1058 VCLEFT_vehNm: 6 VEH
 SG_ VCLEFT_nmDebugWakeUp : 16|32@1+ (1,0) [0|4294967295] ""  gtw
 SG_ VCLEFT_nmWakeUpReason : 8|4@1+ (1,0) [0|15] ""  gtw
 SG_ VCLEFT_nmKeepAwakeReason : 4|4@1+ (1,0) [0|15] ""  gtw
 SG_ VCLEFT_nmWakeUpBus : 1|1@1+ (1,0) [0|1] ""  X
 SG_ VCLEFT_nmGoingToSleep : 0|1@1+ (1,0) [0|1] ""  X

BO_ 1842 XCP_bmsRequest: 8 VEH
 SG_ XCP_bmsRequestData : 7|64@0+ (1,0) [0|18446744073709551615] ""  bms

BO_ 1283 VCRIGHT_bootID: 8 VEH
 SG_ VCRIGHT_bootFirmwareType : 63|8@0+ (1,0) [0|255] ""  X
 SG_ VCRIGHT_bootUsageId : 39|16@0+ (1,0) [0|65535] ""  X
 SG_ VCRIGHT_bootAssemblyId : 31|8@0+ (1,0) [0|255] ""  X
 SG_ VCRIGHT_bootPcbaId : 23|8@0+ (1,0) [0|255] ""  X
 SG_ VCRIGHT_bootComponentId : 7|16@0+ (1,0) [0|65535] ""  X

BA_DEF_ SG_  "SystemSignalLongSymbol" STRING ;
BA_DEF_DEF_  "SystemSignalLongSymbol" "";
BA_ "SystemSignalLongSymbol" SG_ 1343 BMS_a055_invalidModuleThermistor "BMS_a055_invalidModuleThermistorData";
BA_ "SystemSignalLongSymbol" SG_ 1343 BMS_a055_invalidAmbientTemperatu "BMS_a055_invalidAmbientTemperature";
BA_ "SystemSignalLongSymbol" SG_ 1343 BMS_a055_invalidPtInletTemperatu "BMS_a055_invalidPtInletTemperature";
BA_ "SystemSignalLongSymbol" SG_ 1343 BMS_a022_chargeAccumulatorViolat "BMS_a022_chargeAccumulatorViolation";
BA_ "SystemSignalLongSymbol" SG_ 1343 BMS_a157_HVP_bmsChargeRegulation "BMS_a157_HVP_bmsChargeRegulationMia";
VAL_ 1343 BMS_a039_state 5 "BMS_CLEAR_FAULT" 6 "BMS_FAULT" 4 "BMS_FEIM" 0 "BMS_STANDBY" 2 "BMS_SUPPORT" 9 "BMS_SNA" 1 "BMS_DRIVE" 8 "BMS_TEST" 7 "BMS_WELD" 3 "BMS_CHARGE" ;
VAL_ 1343 BMS_a123_state 5 "BMS_CLEAR_FAULT" 6 "BMS_FAULT" 4 "BMS_FEIM" 0 "BMS_STANDBY" 2 "BMS_SUPPORT" 9 "BMS_SNA" 1 "BMS_DRIVE" 8 "BMS_TEST" 7 "BMS_WELD" 3 "BMS_CHARGE" ;
VAL_ 1343 BMS_a082_fourthAlertId 144 "BMS_a144_Hvp_Config_Mismatch" 75 "BMS_a075_SW_Chg_Disable_Failure" 36 "BMS_a036_SW_HvpHvilFault" 170 "BMS_a170_SW_Limp_Mode" 25 "BMS_a025_SW_PwrBalance_Anomaly" 35 "BMS_a035_SW_Isolation" 99 "BMS_a099_SW_BMB_Communication" 88 "BMS_a088_SW_VcFront_MIA_InDrive" 91 "BMS_a091_SW_ChargePort_MIA" 51 "BMS_a051_SW_HVC_Vref_Bad" 61 "BMS_a061_robinBrickOverVoltage" 166 "BMS_a166_SW_Pack_Full_Weld" 17 "BMS_a017_SW_Brick_OV" 59 "BMS_a059_SW_Pack_Voltage_Sensing" 63 "BMS_a063_SW_ChargePort_Fault" 149 "BMS_a149_SW_Missing_Config_Block" 168 "BMS_a168_SW_FC_Full_Weld" 127 "BMS_a127_SW_shunt_SNA" 130 "BMS_a130_IO_CAN_Error" 132 "BMS_a132_HW_BMB_OTP_Uncorrctbl" 76 "BMS_a076_SW_Dch_While_Charging" 161 "BMS_a161_SW_DI_Open_Request" 82 "BMS_a082_SW_Ctr_Force_Open" 39 "BMS_a039_SW_DC_Link_Over_Voltage" 179 "BMS_a179_SW_Hvp_12V_Fault" 41 "BMS_a041_SW_Power_On_Reset" 62 "BMS_a062_SW_BrickV_Imbalance" 164 "BMS_a164_SW_Uncontrolled_Regen" 26 "BMS_a026_SW_HFCurrent_Anomaly" 128 "BMS_a128_SW_shunt_MIA" 131 "BMS_a131_Bleed_FET_Failure" 171 "BMS_a171_SW_Stack_Voltage_Sense" 176 "BMS_a176_SW_GracefulPowerOff" 137 "BMS_a137_SW_Brick_UV_Warning" 159 "BMS_a159_SW_HVP_ECU_Error" 169 "BMS_a169_SW_FC_Pack_Weld" 138 "BMS_a138_SW_Brick_OV_Warning" 162 "BMS_a162_SW_No_Power_For_Support" 22 "BMS_a022_SW_Over_Current" 134 "BMS_a134_SW_Delayed_Ctr_Off" 21 "BMS_a021_SW_Dr_Limits_Regulation" 180 "BMS_a180_SW_ECU_reset_blocked" 174 "BMS_a174_SW_Charge_Failure" 136 "BMS_a136_SW_Module_OT_Warning" 43 "BMS_a043_SW_Watch_Dog_Reset" 37 "BMS_a037_SW_Flood_Port_Open" 44 "BMS_a044_SW_Assertion" 165 "BMS_a165_SW_Pack_Partial_Weld" 122 "BMS_a122_SW_BMS_Therm_Irrational" 163 "BMS_a163_SW_Contactor_Mismatch" 48 "BMS_a048_SW_Log_Upload_Request" 158 "BMS_a158_SW_HVP_HVI_Comms" 81 "BMS_a081_SW_Ctr_Close_Blocked" 23 "BMS_a023_SW_Stack_OV" 54 "BMS_a054_SW_Ver_Supply_Fault" 94 "BMS_a094_SW_Drive_Inverter_MIA" 42 "BMS_a042_SW_MPU_Error" 46 "BMS_a046_SW_Task_Stack_Usage" 47 "BMS_a047_SW_Task_Stack_Overflow" 18 "BMS_a018_SW_Brick_UV" 123 "BMS_a123_SW_Internal_Isolation" 0 "BMS_ALERT_DO_NOT_USE_ZERO" 139 "BMS_a139_SW_DC_Link_V_Irrational" 24 "BMS_a024_SW_Islanded_Brick" 167 "BMS_a167_SW_FC_Partial_Weld" 90 "BMS_a090_SW_Gateway_MIA" 50 "BMS_a050_SW_Brick_Voltage_MIA" 178 "BMS_a178_SW_Uncontrolled_Regen_PwrB" 77 "BMS_a077_SW_Charger_Regulation" 146 "BMS_a146_SW_Brick_Overdischarged" 151 "BMS_a151_SW_external_isolation" 69 "BMS_a069_SW_Low_Power" 145 "BMS_a145_SW_SOC_Change" 121 "BMS_a121_SW_NVRAM_Config_Error" 55 "BMS_a055_SW_HvChain_Model_Fault" 92 "BMS_a092_SW_ChargePort_Mia_On_Hvs" 19 "BMS_a019_SW_Module_OT" 45 "BMS_a045_SW_Exception" 71 "BMS_a071_SW_SM_TransCon_Not_Met" 87 "BMS_a087_SW_Feim_Test_Blocked" 106 "BMS_a106_SW_All_Module_Tsense" 1 "BMS_a001_Pack_Config_Mismatch" 52 "BMS_a052_SW_PCS_MIA" 53 "BMS_a053_SW_ThermalModel_Sanity" 105 "BMS_a105_SW_One_Module_Tsense" 84 "BMS_a084_SW_Sleep_Wake_Aborted" 129 "BMS_a129_SW_VSH_Failure" 64 "BMS_a064_SW_SOC_Imbalance" 83 "BMS_a083_SW_Ctr_Close_Failure" 60 "BMS_a060_SW_Leakage_Test_Failure" 34 "BMS_a034_SW_Passive_Isolation" 107 "BMS_a107_SW_Stack_Voltage_MIA" 89 "BMS_a089_SW_VcFront_MIA" 156 "BMS_a156_SW_BMB_Vref_bad" 141 "BMS_a141_SW_BMB_Status_Warning" 157 "BMS_a157_SW_HVP_HVS_Comms" ;
VAL_ 1343 BMS_a034_state 5 "BMS_CLEAR_FAULT" 6 "BMS_FAULT" 4 "BMS_FEIM" 0 "BMS_STANDBY" 2 "BMS_SUPPORT" 9 "BMS_SNA" 1 "BMS_DRIVE" 8 "BMS_TEST" 7 "BMS_WELD" 3 "BMS_CHARGE" ;
VAL_ 1343 BMS_a081_fourthBlockingAlertId 144 "BMS_a144_Hvp_Config_Mismatch" 75 "BMS_a075_SW_Chg_Disable_Failure" 36 "BMS_a036_SW_HvpHvilFault" 170 "BMS_a170_SW_Limp_Mode" 25 "BMS_a025_SW_PwrBalance_Anomaly" 35 "BMS_a035_SW_Isolation" 99 "BMS_a099_SW_BMB_Communication" 88 "BMS_a088_SW_VcFront_MIA_InDrive" 91 "BMS_a091_SW_ChargePort_MIA" 51 "BMS_a051_SW_HVC_Vref_Bad" 61 "BMS_a061_robinBrickOverVoltage" 166 "BMS_a166_SW_Pack_Full_Weld" 17 "BMS_a017_SW_Brick_OV" 59 "BMS_a059_SW_Pack_Voltage_Sensing" 63 "BMS_a063_SW_ChargePort_Fault" 149 "BMS_a149_SW_Missing_Config_Block" 168 "BMS_a168_SW_FC_Full_Weld" 127 "BMS_a127_SW_shunt_SNA" 130 "BMS_a130_IO_CAN_Error" 132 "BMS_a132_HW_BMB_OTP_Uncorrctbl" 76 "BMS_a076_SW_Dch_While_Charging" 161 "BMS_a161_SW_DI_Open_Request" 82 "BMS_a082_SW_Ctr_Force_Open" 39 "BMS_a039_SW_DC_Link_Over_Voltage" 179 "BMS_a179_SW_Hvp_12V_Fault" 41 "BMS_a041_SW_Power_On_Reset" 62 "BMS_a062_SW_BrickV_Imbalance" 164 "BMS_a164_SW_Uncontrolled_Regen" 26 "BMS_a026_SW_HFCurrent_Anomaly" 128 "BMS_a128_SW_shunt_MIA" 131 "BMS_a131_Bleed_FET_Failure" 171 "BMS_a171_SW_Stack_Voltage_Sense" 176 "BMS_a176_SW_GracefulPowerOff" 137 "BMS_a137_SW_Brick_UV_Warning" 159 "BMS_a159_SW_HVP_ECU_Error" 169 "BMS_a169_SW_FC_Pack_Weld" 138 "BMS_a138_SW_Brick_OV_Warning" 162 "BMS_a162_SW_No_Power_For_Support" 22 "BMS_a022_SW_Over_Current" 134 "BMS_a134_SW_Delayed_Ctr_Off" 21 "BMS_a021_SW_Dr_Limits_Regulation" 180 "BMS_a180_SW_ECU_reset_blocked" 174 "BMS_a174_SW_Charge_Failure" 136 "BMS_a136_SW_Module_OT_Warning" 43 "BMS_a043_SW_Watch_Dog_Reset" 37 "BMS_a037_SW_Flood_Port_Open" 44 "BMS_a044_SW_Assertion" 165 "BMS_a165_SW_Pack_Partial_Weld" 122 "BMS_a122_SW_BMS_Therm_Irrational" 163 "BMS_a163_SW_Contactor_Mismatch" 48 "BMS_a048_SW_Log_Upload_Request" 158 "BMS_a158_SW_HVP_HVI_Comms" 81 "BMS_a081_SW_Ctr_Close_Blocked" 23 "BMS_a023_SW_Stack_OV" 54 "BMS_a054_SW_Ver_Supply_Fault" 94 "BMS_a094_SW_Drive_Inverter_MIA" 42 "BMS_a042_SW_MPU_Error" 46 "BMS_a046_SW_Task_Stack_Usage" 47 "BMS_a047_SW_Task_Stack_Overflow" 18 "BMS_a018_SW_Brick_UV" 123 "BMS_a123_SW_Internal_Isolation" 0 "BMS_ALERT_DO_NOT_USE_ZERO" 139 "BMS_a139_SW_DC_Link_V_Irrational" 24 "BMS_a024_SW_Islanded_Brick" 167 "BMS_a167_SW_FC_Partial_Weld" 90 "BMS_a090_SW_Gateway_MIA" 50 "BMS_a050_SW_Brick_Voltage_MIA" 178 "BMS_a178_SW_Uncontrolled_Regen_PwrB" 77 "BMS_a077_SW_Charger_Regulation" 146 "BMS_a146_SW_Brick_Overdischarged" 151 "BMS_a151_SW_external_isolation" 69 "BMS_a069_SW_Low_Power" 145 "BMS_a145_SW_SOC_Change" 121 "BMS_a121_SW_NVRAM_Config_Error" 55 "BMS_a055_SW_HvChain_Model_Fault" 92 "BMS_a092_SW_ChargePort_Mia_On_Hvs" 19 "BMS_a019_SW_Module_OT" 45 "BMS_a045_SW_Exception" 71 "BMS_a071_SW_SM_TransCon_Not_Met" 87 "BMS_a087_SW_Feim_Test_Blocked" 106 "BMS_a106_SW_All_Module_Tsense" 1 "BMS_a001_Pack_Config_Mismatch" 52 "BMS_a052_SW_PCS_MIA" 53 "BMS_a053_SW_ThermalModel_Sanity" 105 "BMS_a105_SW_One_Module_Tsense" 84 "BMS_a084_SW_Sleep_Wake_Aborted" 129 "BMS_a129_SW_VSH_Failure" 64 "BMS_a064_SW_SOC_Imbalance" 83 "BMS_a083_SW_Ctr_Close_Failure" 60 "BMS_a060_SW_Leakage_Test_Failure" 34 "BMS_a034_SW_Passive_Isolation" 107 "BMS_a107_SW_Stack_Voltage_MIA" 89 "BMS_a089_SW_VcFront_MIA" 156 "BMS_a156_SW_BMB_Vref_bad" 141 "BMS_a141_SW_BMB_Status_Warning" 157 "BMS_a157_SW_HVP_HVS_Comms" ;
VAL_ 1343 BMS_a084_vcfResource 1 "POWERING_DOWN" 2 "POWERING_UP" 4 "MIA" 3 "SILENT" 0 "OFF" 5 "ON" ;
VAL_ 1343 BMS_a081_thirdBlockingAlertId 144 "BMS_a144_Hvp_Config_Mismatch" 75 "BMS_a075_SW_Chg_Disable_Failure" 36 "BMS_a036_SW_HvpHvilFault" 170 "BMS_a170_SW_Limp_Mode" 25 "BMS_a025_SW_PwrBalance_Anomaly" 35 "BMS_a035_SW_Isolation" 99 "BMS_a099_SW_BMB_Communication" 88 "BMS_a088_SW_VcFront_MIA_InDrive" 91 "BMS_a091_SW_ChargePort_MIA" 51 "BMS_a051_SW_HVC_Vref_Bad" 61 "BMS_a061_robinBrickOverVoltage" 166 "BMS_a166_SW_Pack_Full_Weld" 17 "BMS_a017_SW_Brick_OV" 59 "BMS_a059_SW_Pack_Voltage_Sensing" 63 "BMS_a063_SW_ChargePort_Fault" 149 "BMS_a149_SW_Missing_Config_Block" 168 "BMS_a168_SW_FC_Full_Weld" 127 "BMS_a127_SW_shunt_SNA" 130 "BMS_a130_IO_CAN_Error" 132 "BMS_a132_HW_BMB_OTP_Uncorrctbl" 76 "BMS_a076_SW_Dch_While_Charging" 161 "BMS_a161_SW_DI_Open_Request" 82 "BMS_a082_SW_Ctr_Force_Open" 39 "BMS_a039_SW_DC_Link_Over_Voltage" 179 "BMS_a179_SW_Hvp_12V_Fault" 41 "BMS_a041_SW_Power_On_Reset" 62 "BMS_a062_SW_BrickV_Imbalance" 164 "BMS_a164_SW_Uncontrolled_Regen" 26 "BMS_a026_SW_HFCurrent_Anomaly" 128 "BMS_a128_SW_shunt_MIA" 131 "BMS_a131_Bleed_FET_Failure" 171 "BMS_a171_SW_Stack_Voltage_Sense" 176 "BMS_a176_SW_GracefulPowerOff" 137 "BMS_a137_SW_Brick_UV_Warning" 159 "BMS_a159_SW_HVP_ECU_Error" 169 "BMS_a169_SW_FC_Pack_Weld" 138 "BMS_a138_SW_Brick_OV_Warning" 162 "BMS_a162_SW_No_Power_For_Support" 22 "BMS_a022_SW_Over_Current" 134 "BMS_a134_SW_Delayed_Ctr_Off" 21 "BMS_a021_SW_Dr_Limits_Regulation" 180 "BMS_a180_SW_ECU_reset_blocked" 174 "BMS_a174_SW_Charge_Failure" 136 "BMS_a136_SW_Module_OT_Warning" 43 "BMS_a043_SW_Watch_Dog_Reset" 37 "BMS_a037_SW_Flood_Port_Open" 44 "BMS_a044_SW_Assertion" 165 "BMS_a165_SW_Pack_Partial_Weld" 122 "BMS_a122_SW_BMS_Therm_Irrational" 163 "BMS_a163_SW_Contactor_Mismatch" 48 "BMS_a048_SW_Log_Upload_Request" 158 "BMS_a158_SW_HVP_HVI_Comms" 81 "BMS_a081_SW_Ctr_Close_Blocked" 23 "BMS_a023_SW_Stack_OV" 54 "BMS_a054_SW_Ver_Supply_Fault" 94 "BMS_a094_SW_Drive_Inverter_MIA" 42 "BMS_a042_SW_MPU_Error" 46 "BMS_a046_SW_Task_Stack_Usage" 47 "BMS_a047_SW_Task_Stack_Overflow" 18 "BMS_a018_SW_Brick_UV" 123 "BMS_a123_SW_Internal_Isolation" 0 "BMS_ALERT_DO_NOT_USE_ZERO" 139 "BMS_a139_SW_DC_Link_V_Irrational" 24 "BMS_a024_SW_Islanded_Brick" 167 "BMS_a167_SW_FC_Partial_Weld" 90 "BMS_a090_SW_Gateway_MIA" 50 "BMS_a050_SW_Brick_Voltage_MIA" 178 "BMS_a178_SW_Uncontrolled_Regen_PwrB" 77 "BMS_a077_SW_Charger_Regulation" 146 "BMS_a146_SW_Brick_Overdischarged" 151 "BMS_a151_SW_external_isolation" 69 "BMS_a069_SW_Low_Power" 145 "BMS_a145_SW_SOC_Change" 121 "BMS_a121_SW_NVRAM_Config_Error" 55 "BMS_a055_SW_HvChain_Model_Fault" 92 "BMS_a092_SW_ChargePort_Mia_On_Hvs" 19 "BMS_a019_SW_Module_OT" 45 "BMS_a045_SW_Exception" 71 "BMS_a071_SW_SM_TransCon_Not_Met" 87 "BMS_a087_SW_Feim_Test_Blocked" 106 "BMS_a106_SW_All_Module_Tsense" 1 "BMS_a001_Pack_Config_Mismatch" 52 "BMS_a052_SW_PCS_MIA" 53 "BMS_a053_SW_ThermalModel_Sanity" 105 "BMS_a105_SW_One_Module_Tsense" 84 "BMS_a084_SW_Sleep_Wake_Aborted" 129 "BMS_a129_SW_VSH_Failure" 64 "BMS_a064_SW_SOC_Imbalance" 83 "BMS_a083_SW_Ctr_Close_Failure" 60 "BMS_a060_SW_Leakage_Test_Failure" 34 "BMS_a034_SW_Passive_Isolation" 107 "BMS_a107_SW_Stack_Voltage_MIA" 89 "BMS_a089_SW_VcFront_MIA" 156 "BMS_a156_SW_BMB_Vref_bad" 141 "BMS_a141_SW_BMB_Status_Warning" 157 "BMS_a157_SW_HVP_HVS_Comms" ;
VAL_ 1343 BMS_a082_thirdAlertId 144 "BMS_a144_Hvp_Config_Mismatch" 75 "BMS_a075_SW_Chg_Disable_Failure" 36 "BMS_a036_SW_HvpHvilFault" 170 "BMS_a170_SW_Limp_Mode" 25 "BMS_a025_SW_PwrBalance_Anomaly" 35 "BMS_a035_SW_Isolation" 99 "BMS_a099_SW_BMB_Communication" 88 "BMS_a088_SW_VcFront_MIA_InDrive" 91 "BMS_a091_SW_ChargePort_MIA" 51 "BMS_a051_SW_HVC_Vref_Bad" 61 "BMS_a061_robinBrickOverVoltage" 166 "BMS_a166_SW_Pack_Full_Weld" 17 "BMS_a017_SW_Brick_OV" 59 "BMS_a059_SW_Pack_Voltage_Sensing" 63 "BMS_a063_SW_ChargePort_Fault" 149 "BMS_a149_SW_Missing_Config_Block" 168 "BMS_a168_SW_FC_Full_Weld" 127 "BMS_a127_SW_shunt_SNA" 130 "BMS_a130_IO_CAN_Error" 132 "BMS_a132_HW_BMB_OTP_Uncorrctbl" 76 "BMS_a076_SW_Dch_While_Charging" 161 "BMS_a161_SW_DI_Open_Request" 82 "BMS_a082_SW_Ctr_Force_Open" 39 "BMS_a039_SW_DC_Link_Over_Voltage" 179 "BMS_a179_SW_Hvp_12V_Fault" 41 "BMS_a041_SW_Power_On_Reset" 62 "BMS_a062_SW_BrickV_Imbalance" 164 "BMS_a164_SW_Uncontrolled_Regen" 26 "BMS_a026_SW_HFCurrent_Anomaly" 128 "BMS_a128_SW_shunt_MIA" 131 "BMS_a131_Bleed_FET_Failure" 171 "BMS_a171_SW_Stack_Voltage_Sense" 176 "BMS_a176_SW_GracefulPowerOff" 137 "BMS_a137_SW_Brick_UV_Warning" 159 "BMS_a159_SW_HVP_ECU_Error" 169 "BMS_a169_SW_FC_Pack_Weld" 138 "BMS_a138_SW_Brick_OV_Warning" 162 "BMS_a162_SW_No_Power_For_Support" 22 "BMS_a022_SW_Over_Current" 134 "BMS_a134_SW_Delayed_Ctr_Off" 21 "BMS_a021_SW_Dr_Limits_Regulation" 180 "BMS_a180_SW_ECU_reset_blocked" 174 "BMS_a174_SW_Charge_Failure" 136 "BMS_a136_SW_Module_OT_Warning" 43 "BMS_a043_SW_Watch_Dog_Reset" 37 "BMS_a037_SW_Flood_Port_Open" 44 "BMS_a044_SW_Assertion" 165 "BMS_a165_SW_Pack_Partial_Weld" 122 "BMS_a122_SW_BMS_Therm_Irrational" 163 "BMS_a163_SW_Contactor_Mismatch" 48 "BMS_a048_SW_Log_Upload_Request" 158 "BMS_a158_SW_HVP_HVI_Comms" 81 "BMS_a081_SW_Ctr_Close_Blocked" 23 "BMS_a023_SW_Stack_OV" 54 "BMS_a054_SW_Ver_Supply_Fault" 94 "BMS_a094_SW_Drive_Inverter_MIA" 42 "BMS_a042_SW_MPU_Error" 46 "BMS_a046_SW_Task_Stack_Usage" 47 "BMS_a047_SW_Task_Stack_Overflow" 18 "BMS_a018_SW_Brick_UV" 123 "BMS_a123_SW_Internal_Isolation" 0 "BMS_ALERT_DO_NOT_USE_ZERO" 139 "BMS_a139_SW_DC_Link_V_Irrational" 24 "BMS_a024_SW_Islanded_Brick" 167 "BMS_a167_SW_FC_Partial_Weld" 90 "BMS_a090_SW_Gateway_MIA" 50 "BMS_a050_SW_Brick_Voltage_MIA" 178 "BMS_a178_SW_Uncontrolled_Regen_PwrB" 77 "BMS_a077_SW_Charger_Regulation" 146 "BMS_a146_SW_Brick_Overdischarged" 151 "BMS_a151_SW_external_isolation" 69 "BMS_a069_SW_Low_Power" 145 "BMS_a145_SW_SOC_Change" 121 "BMS_a121_SW_NVRAM_Config_Error" 55 "BMS_a055_SW_HvChain_Model_Fault" 92 "BMS_a092_SW_ChargePort_Mia_On_Hvs" 19 "BMS_a019_SW_Module_OT" 45 "BMS_a045_SW_Exception" 71 "BMS_a071_SW_SM_TransCon_Not_Met" 87 "BMS_a087_SW_Feim_Test_Blocked" 106 "BMS_a106_SW_All_Module_Tsense" 1 "BMS_a001_Pack_Config_Mismatch" 52 "BMS_a052_SW_PCS_MIA" 53 "BMS_a053_SW_ThermalModel_Sanity" 105 "BMS_a105_SW_One_Module_Tsense" 84 "BMS_a084_SW_Sleep_Wake_Aborted" 129 "BMS_a129_SW_VSH_Failure" 64 "BMS_a064_SW_SOC_Imbalance" 83 "BMS_a083_SW_Ctr_Close_Failure" 60 "BMS_a060_SW_Leakage_Test_Failure" 34 "BMS_a034_SW_Passive_Isolation" 107 "BMS_a107_SW_Stack_Voltage_MIA" 89 "BMS_a089_SW_VcFront_MIA" 156 "BMS_a156_SW_BMB_Vref_bad" 141 "BMS_a141_SW_BMB_Status_Warning" 157 "BMS_a157_SW_HVP_HVS_Comms" ;
VAL_ 1343 BMS_a084_pcsResource 1 "POWERING_DOWN" 2 "POWERING_UP" 4 "MIA" 3 "SILENT" 0 "OFF" 5 "ON" ;
VAL_ 1343 BMS_a039_packContactorState 7 "CONTACTOR_SET_STATE_WELDED" 3 "CONTACTOR_SET_STATE_BLOCKED" 5 "CONTACTOR_SET_STATE_CLOSED" 4 "CONTACTOR_SET_STATE_OPENING" 8 "CONTACTOR_SET_STATE_POSITIVE_CLOSED" 6 "CONTACTOR_SET_STATE_PARTIAL_WELD" 2 "CONTACTOR_SET_STATE_CLOSING" 0 "CONTACTOR_SET_STATE_SNA" 1 "CONTACTOR_SET_STATE_OPEN" 9 "CONTACTOR_SET_STATE_NEGATIVE_CLOSED" ;
VAL_ 1343 BMS_a084_cpResource 1 "POWERING_DOWN" 2 "POWERING_UP" 4 "MIA" 3 "SILENT" 0 "OFF" 5 "ON" ;
VAL_ 1343 BMS_a081_secondBlockingAlertId 144 "BMS_a144_Hvp_Config_Mismatch" 75 "BMS_a075_SW_Chg_Disable_Failure" 36 "BMS_a036_SW_HvpHvilFault" 170 "BMS_a170_SW_Limp_Mode" 25 "BMS_a025_SW_PwrBalance_Anomaly" 35 "BMS_a035_SW_Isolation" 99 "BMS_a099_SW_BMB_Communication" 88 "BMS_a088_SW_VcFront_MIA_InDrive" 91 "BMS_a091_SW_ChargePort_MIA" 51 "BMS_a051_SW_HVC_Vref_Bad" 61 "BMS_a061_robinBrickOverVoltage" 166 "BMS_a166_SW_Pack_Full_Weld" 17 "BMS_a017_SW_Brick_OV" 59 "BMS_a059_SW_Pack_Voltage_Sensing" 63 "BMS_a063_SW_ChargePort_Fault" 149 "BMS_a149_SW_Missing_Config_Block" 168 "BMS_a168_SW_FC_Full_Weld" 127 "BMS_a127_SW_shunt_SNA" 130 "BMS_a130_IO_CAN_Error" 132 "BMS_a132_HW_BMB_OTP_Uncorrctbl" 76 "BMS_a076_SW_Dch_While_Charging" 161 "BMS_a161_SW_DI_Open_Request" 82 "BMS_a082_SW_Ctr_Force_Open" 39 "BMS_a039_SW_DC_Link_Over_Voltage" 179 "BMS_a179_SW_Hvp_12V_Fault" 41 "BMS_a041_SW_Power_On_Reset" 62 "BMS_a062_SW_BrickV_Imbalance" 164 "BMS_a164_SW_Uncontrolled_Regen" 26 "BMS_a026_SW_HFCurrent_Anomaly" 128 "BMS_a128_SW_shunt_MIA" 131 "BMS_a131_Bleed_FET_Failure" 171 "BMS_a171_SW_Stack_Voltage_Sense" 176 "BMS_a176_SW_GracefulPowerOff" 137 "BMS_a137_SW_Brick_UV_Warning" 159 "BMS_a159_SW_HVP_ECU_Error" 169 "BMS_a169_SW_FC_Pack_Weld" 138 "BMS_a138_SW_Brick_OV_Warning" 162 "BMS_a162_SW_No_Power_For_Support" 22 "BMS_a022_SW_Over_Current" 134 "BMS_a134_SW_Delayed_Ctr_Off" 21 "BMS_a021_SW_Dr_Limits_Regulation" 180 "BMS_a180_SW_ECU_reset_blocked" 174 "BMS_a174_SW_Charge_Failure" 136 "BMS_a136_SW_Module_OT_Warning" 43 "BMS_a043_SW_Watch_Dog_Reset" 37 "BMS_a037_SW_Flood_Port_Open" 44 "BMS_a044_SW_Assertion" 165 "BMS_a165_SW_Pack_Partial_Weld" 122 "BMS_a122_SW_BMS_Therm_Irrational" 163 "BMS_a163_SW_Contactor_Mismatch" 48 "BMS_a048_SW_Log_Upload_Request" 158 "BMS_a158_SW_HVP_HVI_Comms" 81 "BMS_a081_SW_Ctr_Close_Blocked" 23 "BMS_a023_SW_Stack_OV" 54 "BMS_a054_SW_Ver_Supply_Fault" 94 "BMS_a094_SW_Drive_Inverter_MIA" 42 "BMS_a042_SW_MPU_Error" 46 "BMS_a046_SW_Task_Stack_Usage" 47 "BMS_a047_SW_Task_Stack_Overflow" 18 "BMS_a018_SW_Brick_UV" 123 "BMS_a123_SW_Internal_Isolation" 0 "BMS_ALERT_DO_NOT_USE_ZERO" 139 "BMS_a139_SW_DC_Link_V_Irrational" 24 "BMS_a024_SW_Islanded_Brick" 167 "BMS_a167_SW_FC_Partial_Weld" 90 "BMS_a090_SW_Gateway_MIA" 50 "BMS_a050_SW_Brick_Voltage_MIA" 178 "BMS_a178_SW_Uncontrolled_Regen_PwrB" 77 "BMS_a077_SW_Charger_Regulation" 146 "BMS_a146_SW_Brick_Overdischarged" 151 "BMS_a151_SW_external_isolation" 69 "BMS_a069_SW_Low_Power" 145 "BMS_a145_SW_SOC_Change" 121 "BMS_a121_SW_NVRAM_Config_Error" 55 "BMS_a055_SW_HvChain_Model_Fault" 92 "BMS_a092_SW_ChargePort_Mia_On_Hvs" 19 "BMS_a019_SW_Module_OT" 45 "BMS_a045_SW_Exception" 71 "BMS_a071_SW_SM_TransCon_Not_Met" 87 "BMS_a087_SW_Feim_Test_Blocked" 106 "BMS_a106_SW_All_Module_Tsense" 1 "BMS_a001_Pack_Config_Mismatch" 52 "BMS_a052_SW_PCS_MIA" 53 "BMS_a053_SW_ThermalModel_Sanity" 105 "BMS_a105_SW_One_Module_Tsense" 84 "BMS_a084_SW_Sleep_Wake_Aborted" 129 "BMS_a129_SW_VSH_Failure" 64 "BMS_a064_SW_SOC_Imbalance" 83 "BMS_a083_SW_Ctr_Close_Failure" 60 "BMS_a060_SW_Leakage_Test_Failure" 34 "BMS_a034_SW_Passive_Isolation" 107 "BMS_a107_SW_Stack_Voltage_MIA" 89 "BMS_a089_SW_VcFront_MIA" 156 "BMS_a156_SW_BMB_Vref_bad" 141 "BMS_a141_SW_BMB_Status_Warning" 157 "BMS_a157_SW_HVP_HVS_Comms" ;
VAL_ 1343 BMS_a037_floodPort2State 1 "FLOOD_PORT_STATE_ERROR_LOW" 0 "FLOOD_PORT_STATE_SNA" 3 "FLOOD_PORT_STATE_OPEN" 2 "FLOOD_PORT_STATE_CLOSED" 4 "FLOOD_PORT_STATE_ERROR_HIGH" ;
VAL_ 1343 BMS_a035_mode 3 "ISO_VEHICLE_ISOLATION_MODE" 5 "ISO_FEIM_POSITIVE_MODE" 2 "ISO_POSITIVE_ISOLATION_MODE" 4 "ISO_FEIM_NEGATIVE_MODE" 0 "ISO_MODE_RESET" 1 "ISO_NEGATIVE_ISOLATION_MODE" ;
VAL_ 1343 BMS_a082_secondAlertId 144 "BMS_a144_Hvp_Config_Mismatch" 75 "BMS_a075_SW_Chg_Disable_Failure" 36 "BMS_a036_SW_HvpHvilFault" 170 "BMS_a170_SW_Limp_Mode" 25 "BMS_a025_SW_PwrBalance_Anomaly" 35 "BMS_a035_SW_Isolation" 99 "BMS_a099_SW_BMB_Communication" 88 "BMS_a088_SW_VcFront_MIA_InDrive" 91 "BMS_a091_SW_ChargePort_MIA" 51 "BMS_a051_SW_HVC_Vref_Bad" 61 "BMS_a061_robinBrickOverVoltage" 166 "BMS_a166_SW_Pack_Full_Weld" 17 "BMS_a017_SW_Brick_OV" 59 "BMS_a059_SW_Pack_Voltage_Sensing" 63 "BMS_a063_SW_ChargePort_Fault" 149 "BMS_a149_SW_Missing_Config_Block" 168 "BMS_a168_SW_FC_Full_Weld" 127 "BMS_a127_SW_shunt_SNA" 130 "BMS_a130_IO_CAN_Error" 132 "BMS_a132_HW_BMB_OTP_Uncorrctbl" 76 "BMS_a076_SW_Dch_While_Charging" 161 "BMS_a161_SW_DI_Open_Request" 82 "BMS_a082_SW_Ctr_Force_Open" 39 "BMS_a039_SW_DC_Link_Over_Voltage" 179 "BMS_a179_SW_Hvp_12V_Fault" 41 "BMS_a041_SW_Power_On_Reset" 62 "BMS_a062_SW_BrickV_Imbalance" 164 "BMS_a164_SW_Uncontrolled_Regen" 26 "BMS_a026_SW_HFCurrent_Anomaly" 128 "BMS_a128_SW_shunt_MIA" 131 "BMS_a131_Bleed_FET_Failure" 171 "BMS_a171_SW_Stack_Voltage_Sense" 176 "BMS_a176_SW_GracefulPowerOff" 137 "BMS_a137_SW_Brick_UV_Warning" 159 "BMS_a159_SW_HVP_ECU_Error" 169 "BMS_a169_SW_FC_Pack_Weld" 138 "BMS_a138_SW_Brick_OV_Warning" 162 "BMS_a162_SW_No_Power_For_Support" 22 "BMS_a022_SW_Over_Current" 134 "BMS_a134_SW_Delayed_Ctr_Off" 21 "BMS_a021_SW_Dr_Limits_Regulation" 180 "BMS_a180_SW_ECU_reset_blocked" 174 "BMS_a174_SW_Charge_Failure" 136 "BMS_a136_SW_Module_OT_Warning" 43 "BMS_a043_SW_Watch_Dog_Reset" 37 "BMS_a037_SW_Flood_Port_Open" 44 "BMS_a044_SW_Assertion" 165 "BMS_a165_SW_Pack_Partial_Weld" 122 "BMS_a122_SW_BMS_Therm_Irrational" 163 "BMS_a163_SW_Contactor_Mismatch" 48 "BMS_a048_SW_Log_Upload_Request" 158 "BMS_a158_SW_HVP_HVI_Comms" 81 "BMS_a081_SW_Ctr_Close_Blocked" 23 "BMS_a023_SW_Stack_OV" 54 "BMS_a054_SW_Ver_Supply_Fault" 94 "BMS_a094_SW_Drive_Inverter_MIA" 42 "BMS_a042_SW_MPU_Error" 46 "BMS_a046_SW_Task_Stack_Usage" 47 "BMS_a047_SW_Task_Stack_Overflow" 18 "BMS_a018_SW_Brick_UV" 123 "BMS_a123_SW_Internal_Isolation" 0 "BMS_ALERT_DO_NOT_USE_ZERO" 139 "BMS_a139_SW_DC_Link_V_Irrational" 24 "BMS_a024_SW_Islanded_Brick" 167 "BMS_a167_SW_FC_Partial_Weld" 90 "BMS_a090_SW_Gateway_MIA" 50 "BMS_a050_SW_Brick_Voltage_MIA" 178 "BMS_a178_SW_Uncontrolled_Regen_PwrB" 77 "BMS_a077_SW_Charger_Regulation" 146 "BMS_a146_SW_Brick_Overdischarged" 151 "BMS_a151_SW_external_isolation" 69 "BMS_a069_SW_Low_Power" 145 "BMS_a145_SW_SOC_Change" 121 "BMS_a121_SW_NVRAM_Config_Error" 55 "BMS_a055_SW_HvChain_Model_Fault" 92 "BMS_a092_SW_ChargePort_Mia_On_Hvs" 19 "BMS_a019_SW_Module_OT" 45 "BMS_a045_SW_Exception" 71 "BMS_a071_SW_SM_TransCon_Not_Met" 87 "BMS_a087_SW_Feim_Test_Blocked" 106 "BMS_a106_SW_All_Module_Tsense" 1 "BMS_a001_Pack_Config_Mismatch" 52 "BMS_a052_SW_PCS_MIA" 53 "BMS_a053_SW_ThermalModel_Sanity" 105 "BMS_a105_SW_One_Module_Tsense" 84 "BMS_a084_SW_Sleep_Wake_Aborted" 129 "BMS_a129_SW_VSH_Failure" 64 "BMS_a064_SW_SOC_Imbalance" 83 "BMS_a083_SW_Ctr_Close_Failure" 60 "BMS_a060_SW_Leakage_Test_Failure" 34 "BMS_a034_SW_Passive_Isolation" 107 "BMS_a107_SW_Stack_Voltage_MIA" 89 "BMS_a089_SW_VcFront_MIA" 156 "BMS_a156_SW_BMB_Vref_bad" 141 "BMS_a141_SW_BMB_Status_Warning" 157 "BMS_a157_SW_HVP_HVS_Comms" ;
VAL_ 1343 BMS_a084_bmsResource 1 "POWERING_DOWN" 2 "POWERING_UP" 4 "MIA" 3 "SILENT" 0 "OFF" 5 "ON" ;
VAL_ 1343 BMS_a084_hvpResource 1 "POWERING_DOWN" 2 "POWERING_UP" 4 "MIA" 3 "SILENT" 0 "OFF" 5 "ON" ;
VAL_ 1343 BMS_a163_switchStateRequest 4 "SET_REQUEST_CLOSE_NEGATIVE_ONLY" 1 "SET_REQUEST_CLOSE" 3 "SET_REQUEST_OPEN_IMMEDIATELY" 2 "SET_REQUEST_OPEN" 0 "SET_REQUEST_SNA" 5 "SET_REQUEST_CLOSE_POSITIVE_ONLY" ;
VAL_ 1343 BMS_a035_state 5 "BMS_CLEAR_FAULT" 6 "BMS_FAULT" 4 "BMS_FEIM" 0 "BMS_STANDBY" 2 "BMS_SUPPORT" 9 "BMS_SNA" 1 "BMS_DRIVE" 8 "BMS_TEST" 7 "BMS_WELD" 3 "BMS_CHARGE" ;
VAL_ 1343 BMS_a084_vehBusResource 1 "POWERING_DOWN" 2 "POWERING_UP" 4 "MIA" 3 "SILENT" 0 "OFF" 5 "ON" ;
VAL_ 1343 BMS_a082_firstAlertId 144 "BMS_a144_Hvp_Config_Mismatch" 75 "BMS_a075_SW_Chg_Disable_Failure" 36 "BMS_a036_SW_HvpHvilFault" 170 "BMS_a170_SW_Limp_Mode" 25 "BMS_a025_SW_PwrBalance_Anomaly" 35 "BMS_a035_SW_Isolation" 99 "BMS_a099_SW_BMB_Communication" 88 "BMS_a088_SW_VcFront_MIA_InDrive" 91 "BMS_a091_SW_ChargePort_MIA" 51 "BMS_a051_SW_HVC_Vref_Bad" 61 "BMS_a061_robinBrickOverVoltage" 166 "BMS_a166_SW_Pack_Full_Weld" 17 "BMS_a017_SW_Brick_OV" 59 "BMS_a059_SW_Pack_Voltage_Sensing" 63 "BMS_a063_SW_ChargePort_Fault" 149 "BMS_a149_SW_Missing_Config_Block" 168 "BMS_a168_SW_FC_Full_Weld" 127 "BMS_a127_SW_shunt_SNA" 130 "BMS_a130_IO_CAN_Error" 132 "BMS_a132_HW_BMB_OTP_Uncorrctbl" 76 "BMS_a076_SW_Dch_While_Charging" 161 "BMS_a161_SW_DI_Open_Request" 82 "BMS_a082_SW_Ctr_Force_Open" 39 "BMS_a039_SW_DC_Link_Over_Voltage" 179 "BMS_a179_SW_Hvp_12V_Fault" 41 "BMS_a041_SW_Power_On_Reset" 62 "BMS_a062_SW_BrickV_Imbalance" 164 "BMS_a164_SW_Uncontrolled_Regen" 26 "BMS_a026_SW_HFCurrent_Anomaly" 128 "BMS_a128_SW_shunt_MIA" 131 "BMS_a131_Bleed_FET_Failure" 171 "BMS_a171_SW_Stack_Voltage_Sense" 176 "BMS_a176_SW_GracefulPowerOff" 137 "BMS_a137_SW_Brick_UV_Warning" 159 "BMS_a159_SW_HVP_ECU_Error" 169 "BMS_a169_SW_FC_Pack_Weld" 138 "BMS_a138_SW_Brick_OV_Warning" 162 "BMS_a162_SW_No_Power_For_Support" 22 "BMS_a022_SW_Over_Current" 134 "BMS_a134_SW_Delayed_Ctr_Off" 21 "BMS_a021_SW_Dr_Limits_Regulation" 180 "BMS_a180_SW_ECU_reset_blocked" 174 "BMS_a174_SW_Charge_Failure" 136 "BMS_a136_SW_Module_OT_Warning" 43 "BMS_a043_SW_Watch_Dog_Reset" 37 "BMS_a037_SW_Flood_Port_Open" 44 "BMS_a044_SW_Assertion" 165 "BMS_a165_SW_Pack_Partial_Weld" 122 "BMS_a122_SW_BMS_Therm_Irrational" 163 "BMS_a163_SW_Contactor_Mismatch" 48 "BMS_a048_SW_Log_Upload_Request" 158 "BMS_a158_SW_HVP_HVI_Comms" 81 "BMS_a081_SW_Ctr_Close_Blocked" 23 "BMS_a023_SW_Stack_OV" 54 "BMS_a054_SW_Ver_Supply_Fault" 94 "BMS_a094_SW_Drive_Inverter_MIA" 42 "BMS_a042_SW_MPU_Error" 46 "BMS_a046_SW_Task_Stack_Usage" 47 "BMS_a047_SW_Task_Stack_Overflow" 18 "BMS_a018_SW_Brick_UV" 123 "BMS_a123_SW_Internal_Isolation" 0 "BMS_ALERT_DO_NOT_USE_ZERO" 139 "BMS_a139_SW_DC_Link_V_Irrational" 24 "BMS_a024_SW_Islanded_Brick" 167 "BMS_a167_SW_FC_Partial_Weld" 90 "BMS_a090_SW_Gateway_MIA" 50 "BMS_a050_SW_Brick_Voltage_MIA" 178 "BMS_a178_SW_Uncontrolled_Regen_PwrB" 77 "BMS_a077_SW_Charger_Regulation" 146 "BMS_a146_SW_Brick_Overdischarged" 151 "BMS_a151_SW_external_isolation" 69 "BMS_a069_SW_Low_Power" 145 "BMS_a145_SW_SOC_Change" 121 "BMS_a121_SW_NVRAM_Config_Error" 55 "BMS_a055_SW_HvChain_Model_Fault" 92 "BMS_a092_SW_ChargePort_Mia_On_Hvs" 19 "BMS_a019_SW_Module_OT" 45 "BMS_a045_SW_Exception" 71 "BMS_a071_SW_SM_TransCon_Not_Met" 87 "BMS_a087_SW_Feim_Test_Blocked" 106 "BMS_a106_SW_All_Module_Tsense" 1 "BMS_a001_Pack_Config_Mismatch" 52 "BMS_a052_SW_PCS_MIA" 53 "BMS_a053_SW_ThermalModel_Sanity" 105 "BMS_a105_SW_One_Module_Tsense" 84 "BMS_a084_SW_Sleep_Wake_Aborted" 129 "BMS_a129_SW_VSH_Failure" 64 "BMS_a064_SW_SOC_Imbalance" 83 "BMS_a083_SW_Ctr_Close_Failure" 60 "BMS_a060_SW_Leakage_Test_Failure" 34 "BMS_a034_SW_Passive_Isolation" 107 "BMS_a107_SW_Stack_Voltage_MIA" 89 "BMS_a089_SW_VcFront_MIA" 156 "BMS_a156_SW_BMB_Vref_bad" 141 "BMS_a141_SW_BMB_Status_Warning" 157 "BMS_a157_SW_HVP_HVS_Comms" ;
VAL_ 1343 BMS_a146_state 5 "BMS_CLEAR_FAULT" 6 "BMS_FAULT" 4 "BMS_FEIM" 0 "BMS_STANDBY" 2 "BMS_SUPPORT" 9 "BMS_SNA" 1 "BMS_DRIVE" 8 "BMS_TEST" 7 "BMS_WELD" 3 "BMS_CHARGE" ;
VAL_ 1343 BMS_a163_switchState 7 "CONTACTOR_SET_STATE_WELDED" 3 "CONTACTOR_SET_STATE_BLOCKED" 5 "CONTACTOR_SET_STATE_CLOSED" 4 "CONTACTOR_SET_STATE_OPENING" 8 "CONTACTOR_SET_STATE_POSITIVE_CLOSED" 6 "CONTACTOR_SET_STATE_PARTIAL_WELD" 2 "CONTACTOR_SET_STATE_CLOSING" 0 "CONTACTOR_SET_STATE_SNA" 1 "CONTACTOR_SET_STATE_OPEN" 9 "CONTACTOR_SET_STATE_NEGATIVE_CLOSED" ;
VAL_ 1343 BMS_a081_firstBlockingAlertId 144 "BMS_a144_Hvp_Config_Mismatch" 75 "BMS_a075_SW_Chg_Disable_Failure" 36 "BMS_a036_SW_HvpHvilFault" 170 "BMS_a170_SW_Limp_Mode" 25 "BMS_a025_SW_PwrBalance_Anomaly" 35 "BMS_a035_SW_Isolation" 99 "BMS_a099_SW_BMB_Communication" 88 "BMS_a088_SW_VcFront_MIA_InDrive" 91 "BMS_a091_SW_ChargePort_MIA" 51 "BMS_a051_SW_HVC_Vref_Bad" 61 "BMS_a061_robinBrickOverVoltage" 166 "BMS_a166_SW_Pack_Full_Weld" 17 "BMS_a017_SW_Brick_OV" 59 "BMS_a059_SW_Pack_Voltage_Sensing" 63 "BMS_a063_SW_ChargePort_Fault" 149 "BMS_a149_SW_Missing_Config_Block" 168 "BMS_a168_SW_FC_Full_Weld" 127 "BMS_a127_SW_shunt_SNA" 130 "BMS_a130_IO_CAN_Error" 132 "BMS_a132_HW_BMB_OTP_Uncorrctbl" 76 "BMS_a076_SW_Dch_While_Charging" 161 "BMS_a161_SW_DI_Open_Request" 82 "BMS_a082_SW_Ctr_Force_Open" 39 "BMS_a039_SW_DC_Link_Over_Voltage" 179 "BMS_a179_SW_Hvp_12V_Fault" 41 "BMS_a041_SW_Power_On_Reset" 62 "BMS_a062_SW_BrickV_Imbalance" 164 "BMS_a164_SW_Uncontrolled_Regen" 26 "BMS_a026_SW_HFCurrent_Anomaly" 128 "BMS_a128_SW_shunt_MIA" 131 "BMS_a131_Bleed_FET_Failure" 171 "BMS_a171_SW_Stack_Voltage_Sense" 176 "BMS_a176_SW_GracefulPowerOff" 137 "BMS_a137_SW_Brick_UV_Warning" 159 "BMS_a159_SW_HVP_ECU_Error" 169 "BMS_a169_SW_FC_Pack_Weld" 138 "BMS_a138_SW_Brick_OV_Warning" 162 "BMS_a162_SW_No_Power_For_Support" 22 "BMS_a022_SW_Over_Current" 134 "BMS_a134_SW_Delayed_Ctr_Off" 21 "BMS_a021_SW_Dr_Limits_Regulation" 180 "BMS_a180_SW_ECU_reset_blocked" 174 "BMS_a174_SW_Charge_Failure" 136 "BMS_a136_SW_Module_OT_Warning" 43 "BMS_a043_SW_Watch_Dog_Reset" 37 "BMS_a037_SW_Flood_Port_Open" 44 "BMS_a044_SW_Assertion" 165 "BMS_a165_SW_Pack_Partial_Weld" 122 "BMS_a122_SW_BMS_Therm_Irrational" 163 "BMS_a163_SW_Contactor_Mismatch" 48 "BMS_a048_SW_Log_Upload_Request" 158 "BMS_a158_SW_HVP_HVI_Comms" 81 "BMS_a081_SW_Ctr_Close_Blocked" 23 "BMS_a023_SW_Stack_OV" 54 "BMS_a054_SW_Ver_Supply_Fault" 94 "BMS_a094_SW_Drive_Inverter_MIA" 42 "BMS_a042_SW_MPU_Error" 46 "BMS_a046_SW_Task_Stack_Usage" 47 "BMS_a047_SW_Task_Stack_Overflow" 18 "BMS_a018_SW_Brick_UV" 123 "BMS_a123_SW_Internal_Isolation" 0 "BMS_ALERT_DO_NOT_USE_ZERO" 139 "BMS_a139_SW_DC_Link_V_Irrational" 24 "BMS_a024_SW_Islanded_Brick" 167 "BMS_a167_SW_FC_Partial_Weld" 90 "BMS_a090_SW_Gateway_MIA" 50 "BMS_a050_SW_Brick_Voltage_MIA" 178 "BMS_a178_SW_Uncontrolled_Regen_PwrB" 77 "BMS_a077_SW_Charger_Regulation" 146 "BMS_a146_SW_Brick_Overdischarged" 151 "BMS_a151_SW_external_isolation" 69 "BMS_a069_SW_Low_Power" 145 "BMS_a145_SW_SOC_Change" 121 "BMS_a121_SW_NVRAM_Config_Error" 55 "BMS_a055_SW_HvChain_Model_Fault" 92 "BMS_a092_SW_ChargePort_Mia_On_Hvs" 19 "BMS_a019_SW_Module_OT" 45 "BMS_a045_SW_Exception" 71 "BMS_a071_SW_SM_TransCon_Not_Met" 87 "BMS_a087_SW_Feim_Test_Blocked" 106 "BMS_a106_SW_All_Module_Tsense" 1 "BMS_a001_Pack_Config_Mismatch" 52 "BMS_a052_SW_PCS_MIA" 53 "BMS_a053_SW_ThermalModel_Sanity" 105 "BMS_a105_SW_One_Module_Tsense" 84 "BMS_a084_SW_Sleep_Wake_Aborted" 129 "BMS_a129_SW_VSH_Failure" 64 "BMS_a064_SW_SOC_Imbalance" 83 "BMS_a083_SW_Ctr_Close_Failure" 60 "BMS_a060_SW_Leakage_Test_Failure" 34 "BMS_a034_SW_Passive_Isolation" 107 "BMS_a107_SW_Stack_Voltage_MIA" 89 "BMS_a089_SW_VcFront_MIA" 156 "BMS_a156_SW_BMB_Vref_bad" 141 "BMS_a141_SW_BMB_Status_Warning" 157 "BMS_a157_SW_HVP_HVS_Comms" ;
VAL_ 1343 BMS_a084_hvsBusResource 1 "POWERING_DOWN" 2 "POWERING_UP" 4 "MIA" 3 "SILENT" 0 "OFF" 5 "ON" ;
VAL_ 1343 BMS_a099_bmbChainBreakType 3 "BMS_A099_INVALID_BREAK" 1 "BMS_A099_SINGLE_BREAK" 0 "BMS_A099_NONE" 2 "BMS_A099_DOUBLE_BREAK" ;
VAL_ 1343 BMS_a163_switchStateRequestPrev 4 "SET_REQUEST_CLOSE_NEGATIVE_ONLY" 1 "SET_REQUEST_CLOSE" 3 "SET_REQUEST_OPEN_IMMEDIATELY" 2 "SET_REQUEST_OPEN" 0 "SET_REQUEST_SNA" 5 "SET_REQUEST_CLOSE_POSITIVE_ONLY" ;
VAL_ 1343 BMS_a071_state 5 "BMS_CLEAR_FAULT" 6 "BMS_FAULT" 4 "BMS_FEIM" 0 "BMS_STANDBY" 2 "BMS_SUPPORT" 9 "BMS_SNA" 1 "BMS_DRIVE" 8 "BMS_TEST" 7 "BMS_WELD" 3 "BMS_CHARGE" ;
VAL_ 1343 BMS_a084_hviBusResource 1 "POWERING_DOWN" 2 "POWERING_UP" 4 "MIA" 3 "SILENT" 0 "OFF" 5 "ON" ;
VAL_ 1343 BMS_a045_exceptionRegisterType 6 "BMS_A045_CALLTRACE" 4 "BMS_A045_MCSR" 1 "BMS_A045_SRR1" 3 "BMS_A045_DEAR" 0 "BMS_A045_SRR0" 2 "BMS_A045_ESR" 5 "BMS_A045_MCAR" ;
VAL_ 1343 BMS_a001_bmsPackType 6 "BMS_PACK_TYPE_E1_KELVIN" 0 "BMS_PACK_TYPE_UNKNOWN" 1 "BMS_PACK_TYPE_B2" 3 "BMS_PACK_TYPE_C_E3" 7 "BMS_PACK_TYPE_E3_KELVIN_43P" 4 "BMS_PACK_TYPE_SEMI_A" 2 "BMS_PACK_TYPE_C_E1" 8 "BMS_PACK_TYPE_E2" 5 "BMS_PACK_TYPE_E3_KELVIN" ;
VAL_ 1343 BMS_a163_switchStatePrev 7 "CONTACTOR_SET_STATE_WELDED" 3 "CONTACTOR_SET_STATE_BLOCKED" 5 "CONTACTOR_SET_STATE_CLOSED" 4 "CONTACTOR_SET_STATE_OPENING" 8 "CONTACTOR_SET_STATE_POSITIVE_CLOSED" 6 "CONTACTOR_SET_STATE_PARTIAL_WELD" 2 "CONTACTOR_SET_STATE_CLOSING" 0 "CONTACTOR_SET_STATE_SNA" 1 "CONTACTOR_SET_STATE_OPEN" 9 "CONTACTOR_SET_STATE_NEGATIVE_CLOSED" ;
VAL_ 1343 BMS_a084_sleepState 5 "HVS_POWERING_UP" 0 "INIT" 4 "HVS_POWERING_DOWN" 6 "ALL_ON" 2 "STOPPING" 1 "STOP" 3 "SOLO_WAKE" ;
VAL_ 1343 BMS_a121_nvramErrorType 0 "NVRAM_CFG_FILESYSTEM_ERROR" 2 "NVRAM_CFG_ERROR_UNKNOWN" 1 "NVRAM_CFG_BUFFER_SIZE_ERROR" ;
VAL_ 1343 BMS_a062_state 5 "BMS_CLEAR_FAULT" 6 "BMS_FAULT" 4 "BMS_FEIM" 0 "BMS_STANDBY" 2 "BMS_SUPPORT" 9 "BMS_SNA" 1 "BMS_DRIVE" 8 "BMS_TEST" 7 "BMS_WELD" 3 "BMS_CHARGE" ;
VAL_ 1343 BMS_a047_taskID 1 "BMS_TASK_1HZ" 2 "BMS_TASK_10HZ" 3 "BMS_TASK_100HZ" 0 "BMS_TASK_IDLE" 5 "BMS_TASK_UDS" 4 "BMS_TASK_1KHZ" 6 "BMS_TASK_ISR" ;
VAL_ 1343 BMS_a037_floodPort1State 1 "FLOOD_PORT_STATE_ERROR_LOW" 0 "FLOOD_PORT_STATE_SNA" 3 "FLOOD_PORT_STATE_OPEN" 2 "FLOOD_PORT_STATE_CLOSED" 4 "FLOOD_PORT_STATE_ERROR_HIGH" ;
VAL_ 1343 BMS_a071_stateRequest 5 "BMS_CLEAR_FAULT" 6 "BMS_FAULT" 4 "BMS_FEIM" 0 "BMS_STANDBY" 2 "BMS_SUPPORT" 9 "BMS_SNA" 1 "BMS_DRIVE" 8 "BMS_TEST" 7 "BMS_WELD" 3 "BMS_CHARGE" ;
VAL_ 1343 BMS_a043_taskID 1 "BMS_TASK_1HZ" 2 "BMS_TASK_10HZ" 3 "BMS_TASK_100HZ" 0 "BMS_TASK_IDLE" 5 "BMS_TASK_UDS" 4 "BMS_TASK_1KHZ" 6 "BMS_TASK_ISR" ;
VAL_ 1343 BMS_a077_chargeErrType 1 "BMS_A077_CHG_REG_OVERCHARGE" 0 "BMS_A077_CHG_REG_CURRENT_HIGH" ;
VAL_ 1343 BMS_a046_taskID 1 "BMS_TASK_1HZ" 2 "BMS_TASK_10HZ" 3 "BMS_TASK_100HZ" 0 "BMS_TASK_IDLE" 5 "BMS_TASK_UDS" 4 "BMS_TASK_1KHZ" 6 "BMS_TASK_ISR" ;
VAL_ 1343 BMS_a082_stateRequest 5 "BMS_CLEAR_FAULT" 6 "BMS_FAULT" 4 "BMS_FEIM" 0 "BMS_STANDBY" 2 "BMS_SUPPORT" 9 "BMS_SNA" 1 "BMS_DRIVE" 8 "BMS_TEST" 7 "BMS_WELD" 3 "BMS_CHARGE" ;
VAL_ 1343 BMS_a090_GTWmessageTout 8 "BMS_A090_MCU_DRIVERLIMITS" 6 "BMS_A090_GTW_12VSTATUS" 5 "BMS_A090_MCU_ODOMETER" 1 "BMS_A090_MCU_POWER" 7 "BMS_A090_GTW_CARCONFIG2" 4 "BMS_A090_GTW_CARCONFIG" 3 "BMS_A090_GTW_PTNM" 2 "BMS_A090_GTW_BODYSTATUS" 0 "BMS_A090_GTW_COMMANDS" ;
VAL_ 1343 BMS_a083_packContactorRequest 5 "BMS_A083_CTR_REQUEST_FAULT_OPEN" 1 "BMS_A083_CTR_REQUEST_NEG_CLOSED_POS_OPEN" 2 "BMS_A083_CTR_REQUEST_POS_CLOSED_NEG_OPEN" 0 "BMS_A083_CTR_REQUEST_SNA" 3 "BMS_A083_CTR_REQUEST_CLOSED" 4 "BMS_A083_CTR_REQUEST_OPEN" ;
VAL_ 1343 BMS_a075_chargeType 0 "BMS_DC_CHARGE_SESSION" 1 "BMS_AC_CHARGE_SESSION" ;
VAL_ 1343 BMS_a001_gatewayPackType 0 "PACK_50_KWH" 1 "PACK_74_KWH" 2 "PACK_62_KWH" ;
VAL_ 1343 BMS_a081_stateRequest 5 "BMS_CLEAR_FAULT" 6 "BMS_FAULT" 4 "BMS_FEIM" 0 "BMS_STANDBY" 2 "BMS_SUPPORT" 9 "BMS_SNA" 1 "BMS_DRIVE" 8 "BMS_TEST" 7 "BMS_WELD" 3 "BMS_CHARGE" ;
VAL_ 1343 BMS_a044_assertId 10 "BMS_CHARGE_MODULE" 4 "BMS_CAC_MODULE" 6 "BMS_ADC_MODULE" 5 "BMS_BMB_MODULE" 8 "BMS_DRIVE_LIMITS_MODULE" 2 "BMS_POWER_MODULE" 0 "BMS_ENERGY_MODULE" 7 "BMS_VOLTAGE_MONITOR_MODULE" 9 "BMS_SHUNT_MODULE" 1 "BMS_STATE_MACHINE_MODULE" 3 "BMS_SOC_MODULE" ;
VAL_ 1343 BMS_a163_contactorType 1 "FC_CONTACTORS" 0 "PACK_SWITCHES" ;
VAL_ 1343 BMS_alertSet 0 "ALERT_CLEARED" 1 "ALERT_SET" ;
VAL_ 1343 BMS_alertID 144 "BMS_a144_Hvp_Config_Mismatch" 75 "BMS_a075_SW_Chg_Disable_Failure" 36 "BMS_a036_SW_HvpHvilFault" 170 "BMS_a170_SW_Limp_Mode" 25 "BMS_a025_SW_PwrBalance_Anomaly" 35 "BMS_a035_SW_Isolation" 99 "BMS_a099_SW_BMB_Communication" 88 "BMS_a088_SW_VcFront_MIA_InDrive" 91 "BMS_a091_SW_ChargePort_MIA" 51 "BMS_a051_SW_HVC_Vref_Bad" 61 "BMS_a061_robinBrickOverVoltage" 166 "BMS_a166_SW_Pack_Full_Weld" 17 "BMS_a017_SW_Brick_OV" 59 "BMS_a059_SW_Pack_Voltage_Sensing" 63 "BMS_a063_SW_ChargePort_Fault" 149 "BMS_a149_SW_Missing_Config_Block" 168 "BMS_a168_SW_FC_Full_Weld" 127 "BMS_a127_SW_shunt_SNA" 130 "BMS_a130_IO_CAN_Error" 132 "BMS_a132_HW_BMB_OTP_Uncorrctbl" 76 "BMS_a076_SW_Dch_While_Charging" 161 "BMS_a161_SW_DI_Open_Request" 82 "BMS_a082_SW_Ctr_Force_Open" 39 "BMS_a039_SW_DC_Link_Over_Voltage" 179 "BMS_a179_SW_Hvp_12V_Fault" 41 "BMS_a041_SW_Power_On_Reset" 62 "BMS_a062_SW_BrickV_Imbalance" 164 "BMS_a164_SW_Uncontrolled_Regen" 26 "BMS_a026_SW_HFCurrent_Anomaly" 128 "BMS_a128_SW_shunt_MIA" 131 "BMS_a131_Bleed_FET_Failure" 171 "BMS_a171_SW_Stack_Voltage_Sense" 176 "BMS_a176_SW_GracefulPowerOff" 137 "BMS_a137_SW_Brick_UV_Warning" 159 "BMS_a159_SW_HVP_ECU_Error" 169 "BMS_a169_SW_FC_Pack_Weld" 138 "BMS_a138_SW_Brick_OV_Warning" 162 "BMS_a162_SW_No_Power_For_Support" 22 "BMS_a022_SW_Over_Current" 134 "BMS_a134_SW_Delayed_Ctr_Off" 21 "BMS_a021_SW_Dr_Limits_Regulation" 180 "BMS_a180_SW_ECU_reset_blocked" 174 "BMS_a174_SW_Charge_Failure" 136 "BMS_a136_SW_Module_OT_Warning" 43 "BMS_a043_SW_Watch_Dog_Reset" 37 "BMS_a037_SW_Flood_Port_Open" 44 "BMS_a044_SW_Assertion" 165 "BMS_a165_SW_Pack_Partial_Weld" 122 "BMS_a122_SW_BMS_Therm_Irrational" 163 "BMS_a163_SW_Contactor_Mismatch" 48 "BMS_a048_SW_Log_Upload_Request" 158 "BMS_a158_SW_HVP_HVI_Comms" 81 "BMS_a081_SW_Ctr_Close_Blocked" 23 "BMS_a023_SW_Stack_OV" 54 "BMS_a054_SW_Ver_Supply_Fault" 94 "BMS_a094_SW_Drive_Inverter_MIA" 42 "BMS_a042_SW_MPU_Error" 46 "BMS_a046_SW_Task_Stack_Usage" 47 "BMS_a047_SW_Task_Stack_Overflow" 18 "BMS_a018_SW_Brick_UV" 123 "BMS_a123_SW_Internal_Isolation" 0 "BMS_ALERT_DO_NOT_USE_ZERO" 139 "BMS_a139_SW_DC_Link_V_Irrational" 24 "BMS_a024_SW_Islanded_Brick" 167 "BMS_a167_SW_FC_Partial_Weld" 90 "BMS_a090_SW_Gateway_MIA" 50 "BMS_a050_SW_Brick_Voltage_MIA" 178 "BMS_a178_SW_Uncontrolled_Regen_PwrB" 77 "BMS_a077_SW_Charger_Regulation" 146 "BMS_a146_SW_Brick_Overdischarged" 151 "BMS_a151_SW_external_isolation" 69 "BMS_a069_SW_Low_Power" 145 "BMS_a145_SW_SOC_Change" 121 "BMS_a121_SW_NVRAM_Config_Error" 55 "BMS_a055_SW_HvChain_Model_Fault" 92 "BMS_a092_SW_ChargePort_Mia_On_Hvs" 19 "BMS_a019_SW_Module_OT" 45 "BMS_a045_SW_Exception" 71 "BMS_a071_SW_SM_TransCon_Not_Met" 87 "BMS_a087_SW_Feim_Test_Blocked" 106 "BMS_a106_SW_All_Module_Tsense" 1 "BMS_a001_Pack_Config_Mismatch" 52 "BMS_a052_SW_PCS_MIA" 53 "BMS_a053_SW_ThermalModel_Sanity" 105 "BMS_a105_SW_One_Module_Tsense" 84 "BMS_a084_SW_Sleep_Wake_Aborted" 129 "BMS_a129_SW_VSH_Failure" 64 "BMS_a064_SW_SOC_Imbalance" 83 "BMS_a083_SW_Ctr_Close_Failure" 60 "BMS_a060_SW_Leakage_Test_Failure" 34 "BMS_a034_SW_Passive_Isolation" 107 "BMS_a107_SW_Stack_Voltage_MIA" 89 "BMS_a089_SW_VcFront_MIA" 156 "BMS_a156_SW_BMB_Vref_bad" 141 "BMS_a141_SW_BMB_Status_Warning" 157 "BMS_a157_SW_HVP_HVS_Comms" ;
VAL_ 907 APP_solarLoadEstimate 2047 "SNA" ;
VAL_ 907 APP_solarObscurityPercent 255 "SNA" ;
VAL_ 1329 VCSEC_alertClearedID 165 "VCSEC_a165_ephemeralKeyGenerated" 182 "VCSEC_a182_cryptoHighStackUsage" 63 "VCSEC_a063_SwitchFault" 43 "VCSEC_a043_Task1msError" 3 "VCSEC_a003_SWAssertion" 109 "VCSEC_a109_RCM_MIA" 191 "VCSEC_a191_macIDWlistingFailedC" 110 "VCSEC_a110_GTW_MIA" 118 "VCSEC_a118_VCFRONT_MIA" 206 "VCSEC_a206_BLELeftAssertFailure" 61 "VCSEC_a061_XCPConnected" 103 "VCSEC_a103_CP_MIA" 201 "VCSEC_a201_leftEndpointLostComm" 202 "VCSEC_a202_rightEndpointLostComm" 167 "VCSEC_a167_BLECenterSoftReset" 112 "VCSEC_a112_EPBL_MIA" 117 "VCSEC_a117_VCLEFT_MIA" 45 "VCSEC_a045_Task100msError" 183 "VCSEC_a183_centerEndpointRFMia" 198 "VCSEC_a198_BPillarNFCReaderMIA" 2 "VCSEC_a002_PowerLossReset" 42 "VCSEC_a042_HighStackUsage" 41 "VCSEC_a041_HighCPULoad" 193 "VCSEC_a193_macIDWlistingFailedRi" 168 "VCSEC_a168_BLELeftSoftReset" 147 "VCSEC_a147_protobufRXTimeout" 64 "VCSEC_a064_busSleepReqTimeout" 141 "VCSEC_a141_tooFewKeysOnWhitelist" 172 "VCSEC_a172_BLEUnexpectedResetC" 207 "VCSEC_a207_BLERightAssertFailure" 145 "VCSEC_a145_bleGattAlertRe" 161 "VCSEC_a161_hciFaultR" 31 "VCSEC_a031_UDSActive" 143 "VCSEC_a143_bleGattAlertL" 104 "VCSEC_a104_DAS_MIA" 209 "VCSEC_a209_BLECenterAssertFailure" 116 "VCSEC_a116_VCRIGHT_MIA" 154 "VCSEC_a154_srvcCmdTimeoutL" 60 "VCSEC_a060_engineeringBuild" 159 "VCSEC_a159_hciFaultL" 186 "VCSEC_a186_rearEndpointRFMia" 184 "VCSEC_a184_driverEndpointRFMia" 199 "VCSEC_a199_CenterNFCReaderMIA" 97 "VCSEC_a097_CMP_MIA" 98 "VCSEC_a098_DI_THERMAL_MIA" 150 "VCSEC_a150_attrsWentMissingR" 162 "VCSEC_a162_hciFaultRe" 44 "VCSEC_a044_Task10msError" 170 "VCSEC_a170_BLERearSoftReset" 135 "VCSEC_a135_centerEndpointMIA" 101 "VCSEC_a101_PM_MIA" 120 "VCSEC_a120_DI_DRIVE_MIA" 59 "VCSEC_a059_inputResistanceHigh" 187 "VCSEC_a187_badConnectionDropped" 158 "VCSEC_a158_hciFaultC" 142 "VCSEC_a142_bleGattAlertC" 105 "VCSEC_a105_TAS_MIA" 210 "VCSEC_a210_keyDeviceBatteryLow" 62 "VCSEC_a062_XCPWasConnected" 180 "VCSEC_a180_wlistRemovedPermission" 119 "VCSEC_a119_SCCM_MIA" 113 "VCSEC_a113_UI_MIA" 195 "VCSEC_a195_keyMissingInDrive" 204 "VCSEC_a204_SharedSecretsWritten" 106 "VCSEC_a106_PCS_MIA" 13 "VCSEC_a013_AlertManagerFault" 108 "VCSEC_a108_DIS_MIA" 178 "VCSEC_a178_whitelistRemovedKey" 30 "VCSEC_a030_ECULogUploadRequest" 155 "VCSEC_a155_srvcCmdTimeoutR" 111 "VCSEC_a111_EPBR_MIA" 203 "VCSEC_a203_rearEndpointLostComm" 140 "VCSEC_a140_nfcAuthentication" 196 "VCSEC_a196_protobufTXTimeout" 189 "VCSEC_a189_protoExpLengthTooLarge" 151 "VCSEC_a151_attrsWentMissingRe" 102 "VCSEC_a102_PTC_MIA" 169 "VCSEC_a169_BLERightSoftReset" 137 "VCSEC_a137_rightEndpointMIA" 181 "VCSEC_a181_signedMessageFault" 177 "VCSEC_a177_whitelistAddedKey" 133 "VCSEC_a133_alarmTriggered" 100 "VCSEC_a100_CANbus_MIA" 205 "VCSEC_a205_MTUUpdateNotConfirmed" 134 "VCSEC_a134_badCertificate" 148 "VCSEC_a148_keyWhitelistFull" 149 "VCSEC_a149_attrsWentMissingL" 164 "VCSEC_a164_attrsWentMissingC" 185 "VCSEC_a185_passengerEndpointRFMia" 136 "VCSEC_a136_leftEndpointMIA" 179 "VCSEC_a179_wlistAddedPermission" 1 "VCSEC_a001_WatchdogReset" 197 "VCSEC_a197_indicationFault" 153 "VCSEC_a153_srvcCmdTimeoutC" 21 "VCSEC_a021_TaskSchedulerError" 173 "VCSEC_a173_BLEUnexpectedResetL" 188 "VCSEC_a188_protobufDecodeError" 200 "VCSEC_a200_centerEndpointLostComm" 192 "VCSEC_a192_macIDWlistingFailedL" 99 "VCSEC_a099_PARK_MIA" 174 "VCSEC_a174_BLEUnexpectedResetRi" 166 "VCSEC_a166_BLECenterPowerCycled" 15 "VCSEC_a015_NVMMAlert" 10 "VCSEC_a010_ExtSupplyVoltError" 115 "VCSEC_a115_VCSEC_MIA" 22 "VCSEC_a022_TaskInitError" 194 "VCSEC_a194_macIDWlistingFailedRe" 208 "VCSEC_a208_BLERearAssertFailure" 0 "VCSEC_ALERT_DO_NOT_USE_ZERO" 175 "VCSEC_a175_BLEUnexpectedResetRe" 114 "VCSEC_a114_ESP_MIA" 190 "VCSEC_a190_protoTooManyBytes" 156 "VCSEC_a156_srvcCmdTimeoutRe" 46 "VCSEC_a046_Task1000msError" 107 "VCSEC_a107_BMS_MIA" 144 "VCSEC_a144_bleGattAlertR" 138 "VCSEC_a138_rearEndpointMIA" 12 "VCSEC_a012_CPUReset" ;
VAL_ 1139 UI_nmKeepAwakeReason 9 "UI_KEEPAWAKE_REASON_UPDATE_COUNTDOWN" 1 "UI_KEEPAWAKE_REASON_KEEPALIVEACTIVE" 2 "UI_KEEPAWAKE_REASON_GUI_NEVER_SLEEP_SET" 6 "UI_KEEPAWAKE_REASON_UPDATER" 5 "UI_KEEPAWAKE_REASON_MODEM_RESET" 0 "UI_KEEPAWAKE_REASON_NONE_SNA" 15 "UI_KEEPAWAKE_REASON_MULTIPLE" 8 "UI_KEEPAWAKE_REASON_AUTOFUSER" 4 "UI_KEEPAWAKE_REASON_UNKNOWN_REMOTE_REQUEST" 3 "UI_KEEPAWAKE_REASON_PM_CHECKING" 7 "UI_KEEPAWAKE_REASON_HERMES" 10 "UI_KEEPAWAKE_REASON_ECALL_ACTIVE" ;
VAL_ 1280 UI_debugEcuTarget 7 "VCFRONT" 1 "DI" 3 "PM" 5 "BMS" 6 "VCRIGHT" 4 "PMS" 2 "DIS" ;
VAL_ 969 VCSEC_BLEEndpointInfoIndex 2 "BLEENDPOINT_REAR_INFO" 5 "BLEENDPOINT_RIGHT_APP_GITHASH" 6 "BLEENDPOINT_REAR_APP_GITHASH" 0 "BLEENDPOINT_LEFT_INFO" 4 "BLEENDPOINT_LEFT_APP_GITHASH" 3 "BLEENDPOINT_CENTER_INFO" 7 "BLEENDPOINT_CENTER_APP_GITHASH" 1 "BLEENDPOINT_RIGHT_INFO" ;
VAL_ 545 VCFRONT_uiAudioLVState 1 "LV_ON" 2 "LV_GOING_DOWN" 3 "LV_FAULT" 0 "LV_OFF" ;
VAL_ 545 VCFRONT_uiHiCurrentLVState 1 "LV_ON" 2 "LV_GOING_DOWN" 3 "LV_FAULT" 0 "LV_OFF" ;
VAL_ 545 VCFRONT_vcrightHiCurrentLVState 1 "LV_ON" 2 "LV_GOING_DOWN" 3 "LV_FAULT" 0 "LV_OFF" ;
VAL_ 545 VCFRONT_vcleftHiCurrentLVState 1 "LV_ON" 2 "LV_GOING_DOWN" 3 "LV_FAULT" 0 "LV_OFF" ;
VAL_ 545 VCFRONT_ocsLVRequest 1 "LV_ON" 2 "LV_GOING_DOWN" 3 "LV_FAULT" 0 "LV_OFF" ;
VAL_ 545 VCFRONT_oilPumpRearLVRequest 1 "LV_ON" 2 "LV_GOING_DOWN" 3 "LV_FAULT" 0 "LV_OFF" ;
VAL_ 545 VCFRONT_oilPumpFrontLVState 1 "LV_ON" 2 "LV_GOING_DOWN" 3 "LV_FAULT" 0 "LV_OFF" ;
VAL_ 545 VCFRONT_disLVState 1 "LV_ON" 2 "LV_GOING_DOWN" 3 "LV_FAULT" 0 "LV_OFF" ;
VAL_ 545 VCFRONT_diLVRequest 1 "LV_ON" 2 "LV_GOING_DOWN" 3 "LV_FAULT" 0 "LV_OFF" ;
VAL_ 545 VCFRONT_das2HighCurrentLVState 1 "LV_ON" 2 "LV_GOING_DOWN" 3 "LV_FAULT" 0 "LV_OFF" ;
VAL_ 545 VCFRONT_das1HighCurrentLVState 1 "LV_ON" 2 "LV_GOING_DOWN" 3 "LV_FAULT" 0 "LV_OFF" ;
VAL_ 545 VCFRONT_amplifierLVRequest 1 "LV_ON" 2 "LV_GOING_DOWN" 3 "LV_FAULT" 0 "LV_OFF" ;
VAL_ 545 VCFRONT_tunerLVRequest 1 "LV_ON" 2 "LV_GOING_DOWN" 3 "LV_FAULT" 0 "LV_OFF" ;
VAL_ 545 VCFRONT_iBoosterLVState 1 "LV_ON" 2 "LV_GOING_DOWN" 3 "LV_FAULT" 0 "LV_OFF" ;
VAL_ 545 VCFRONT_rcmLVRequest 1 "LV_ON" 2 "LV_GOING_DOWN" 3 "LV_FAULT" 0 "LV_OFF" ;
VAL_ 545 VCFRONT_tpmsLVRequest 1 "LV_ON" 2 "LV_GOING_DOWN" 3 "LV_FAULT" 0 "LV_OFF" ;
VAL_ 545 VCFRONT_sccmLVRequest 1 "LV_ON" 2 "LV_GOING_DOWN" 3 "LV_FAULT" 0 "LV_OFF" ;
VAL_ 545 VCFRONT_pcsLVState 1 "LV_ON" 2 "LV_GOING_DOWN" 3 "LV_FAULT" 0 "LV_OFF" ;
VAL_ 545 VCFRONT_ptcLVRequest 1 "LV_ON" 2 "LV_GOING_DOWN" 3 "LV_FAULT" 0 "LV_OFF" ;
VAL_ 545 VCFRONT_hvacCompLVState 1 "LV_ON" 2 "LV_GOING_DOWN" 3 "LV_FAULT" 0 "LV_OFF" ;
VAL_ 545 VCFRONT_tasLVState 1 "LV_ON" 2 "LV_GOING_DOWN" 3 "LV_FAULT" 0 "LV_OFF" ;
VAL_ 545 VCFRONT_hvcLVRequest 1 "LV_ON" 2 "LV_GOING_DOWN" 3 "LV_FAULT" 0 "LV_OFF" ;
VAL_ 545 VCFRONT_radcLVState 1 "LV_ON" 2 "LV_GOING_DOWN" 3 "LV_FAULT" 0 "LV_OFF" ;
VAL_ 545 VCFRONT_epasLVState 1 "LV_ON" 2 "LV_GOING_DOWN" 3 "LV_FAULT" 0 "LV_OFF" ;
VAL_ 545 VCFRONT_espLVState 1 "LV_ON" 2 "LV_GOING_DOWN" 3 "LV_FAULT" 0 "LV_OFF" ;
VAL_ 545 VCFRONT_parkLVState 1 "LV_ON" 2 "LV_GOING_DOWN" 3 "LV_FAULT" 0 "LV_OFF" ;
VAL_ 545 VCFRONT_cpLVRequest 1 "LV_ON" 2 "LV_GOING_DOWN" 3 "LV_FAULT" 0 "LV_OFF" ;
VAL_ 545 VCFRONT_vehiclePowerState 3 "VEHICLE_POWER_STATE_DRIVE" 1 "VEHICLE_POWER_STATE_CONDITIONING" 2 "VEHICLE_POWER_STATE_ACCESSORY" 0 "VEHICLE_POWER_STATE_OFF" ;
VAL_ 545 VCFRONT_LVPowerStateIndex 0 "Mux0" 1 "Mux1" ;
VAL_ 981 DIS_oilPumpFetCTemp 255 "SNA" ;
VAL_ 981 DIS_oilPumpFetBTemp 255 "SNA" ;
VAL_ 981 DIS_oilPumpFetATemp 255 "SNA" ;
VAL_ 798 CP_matrixIndex 1 "CP_AlertMatrix1" 0 "CP_AlertMatrix0" ;
VAL_ 793 VCSEC_infoAssemblyId 1 "ASSEMBLY1" 255 "ASSEMBLY_SNA" ;
VAL_ 793 VCSEC_infoBuildType 1 "INFO_PLATFORM_BUILD" 3 "INFO_TRACEABLE_CI_BUILD" 4 "INFO_MFG_BUILD" 2 "INFO_LOCAL_BUILD" 0 "INFO_UNKNOWN_BUILD" ;
VAL_ 793 VCSEC_infoIndex 14 "BC_INFO_BOOTLOADER_SVN" 6 "BC_INFO_DEPRECATED_6" 20 "BC_INFO_UDS_PROTOCOL_BOOTCRC" 24 "BC_INFO_SUBCOMPONENT3" 1 "BC_INFO_DEPRECATED_1" 31 "BC_INFO_SUBCOMPONENT4" 19 "BC_INFO_VERSION_DEPRECATED" 10 "BC_INFO_BUILD_HWID_COMPONENTID" 0 "BC_INFO_DEPRECATED_0" 5 "BC_INFO_DEPRECATED_5" 11 "BC_INFO_PCBAID_ASSYID_USAGEID" 18 "BC_INFO_BOOTLOADER_GITHASH" 3 "BC_INFO_DEPRECATED_3" 15 "BC_INFO_BOOTLOADER_CRC" 4 "BC_INFO_DEPRECATED_4" 16 "BC_INFO_SUBCOMPONENT1" 255 "BC_INFO_END" 9 "BC_INFO_DEPRECATED_9" 13 "BC_INFO_APP_CRC" 2 "BC_INFO_DEPRECATED_2" 23 "BC_INFO_SUBCOMPONENT2" 7 "BC_INFO_DEPRECATED_7" 8 "BC_INFO_DEPRECATED_8" 17 "BC_INFO_APP_GITHASH" ;
VAL_ 950 DI_odometer 4294967295 "SNA" ;
VAL_ 1058 VCLEFT_nmWakeUpReason 6 "VCLEFT_WAKEUP_REASON_EXTERIOR_HANDLE" 5 "VCLEFT_WAKEUP_REASON_INTERIOR_HANDLE" 3 "VCLEFT_WAKEUP_REASON_RESET" 2 "VCLEFT_WAKEUP_REASON_SWITCH_INPUT" 1 "VCLEFT_WAKEUP_REASON_ECU_SPECIFIC" 0 "VCLEFT_WAKEUP_REASON_NONE" 7 "VCLEFT_WAKEUP_REASON_BRAKE_SWITCH" 15 "VCLEFT_WAKEUP_REASON_UNKNOWN" 4 "VCLEFT_WAKEUP_REASON_DOOR_LATCH" 8 "VCLEFT_WAKEUP_REASON_LIN_RX" ;
VAL_ 1058 VCLEFT_nmKeepAwakeReason 7 "VCLEFT_KEEPAWAKE_REASON_SEAT" 9 "VCLEFT_KEEPAWAKE_REASON_INTRUSION_SENSOR_TRIGGERED" 14 "VCLEFT_KEEPAWAKE_REASON_OTHER" 5 "VCLEFT_KEEPAWAKE_REASON_EPB_SUMMON_ACTIVE" 4 "VCLEFT_KEEPAWAKE_REASON_CLOSURE_LATCH" 0 "VCLEFT_KEEPAWAKE_REASON_NONE_SNA" 6 "VCLEFT_KEEPAWAKE_REASON_HANDLE_PULLED" 15 "VCLEFT_KEEPAWAKE_REASON_MULTIPLE" 2 "VCLEFT_KEEPAWAKE_REASON_EPB_NOT_SECURE" 3 "VCLEFT_KEEPAWAKE_REASON_BRAKE_SWITCH" 1 "VCLEFT_KEEPAWAKE_REASON_EPB_STATE_NOT_SAVED" 8 "VCLEFT_KEEPAWAKE_REASON_UDS_ACTIVE" ;
